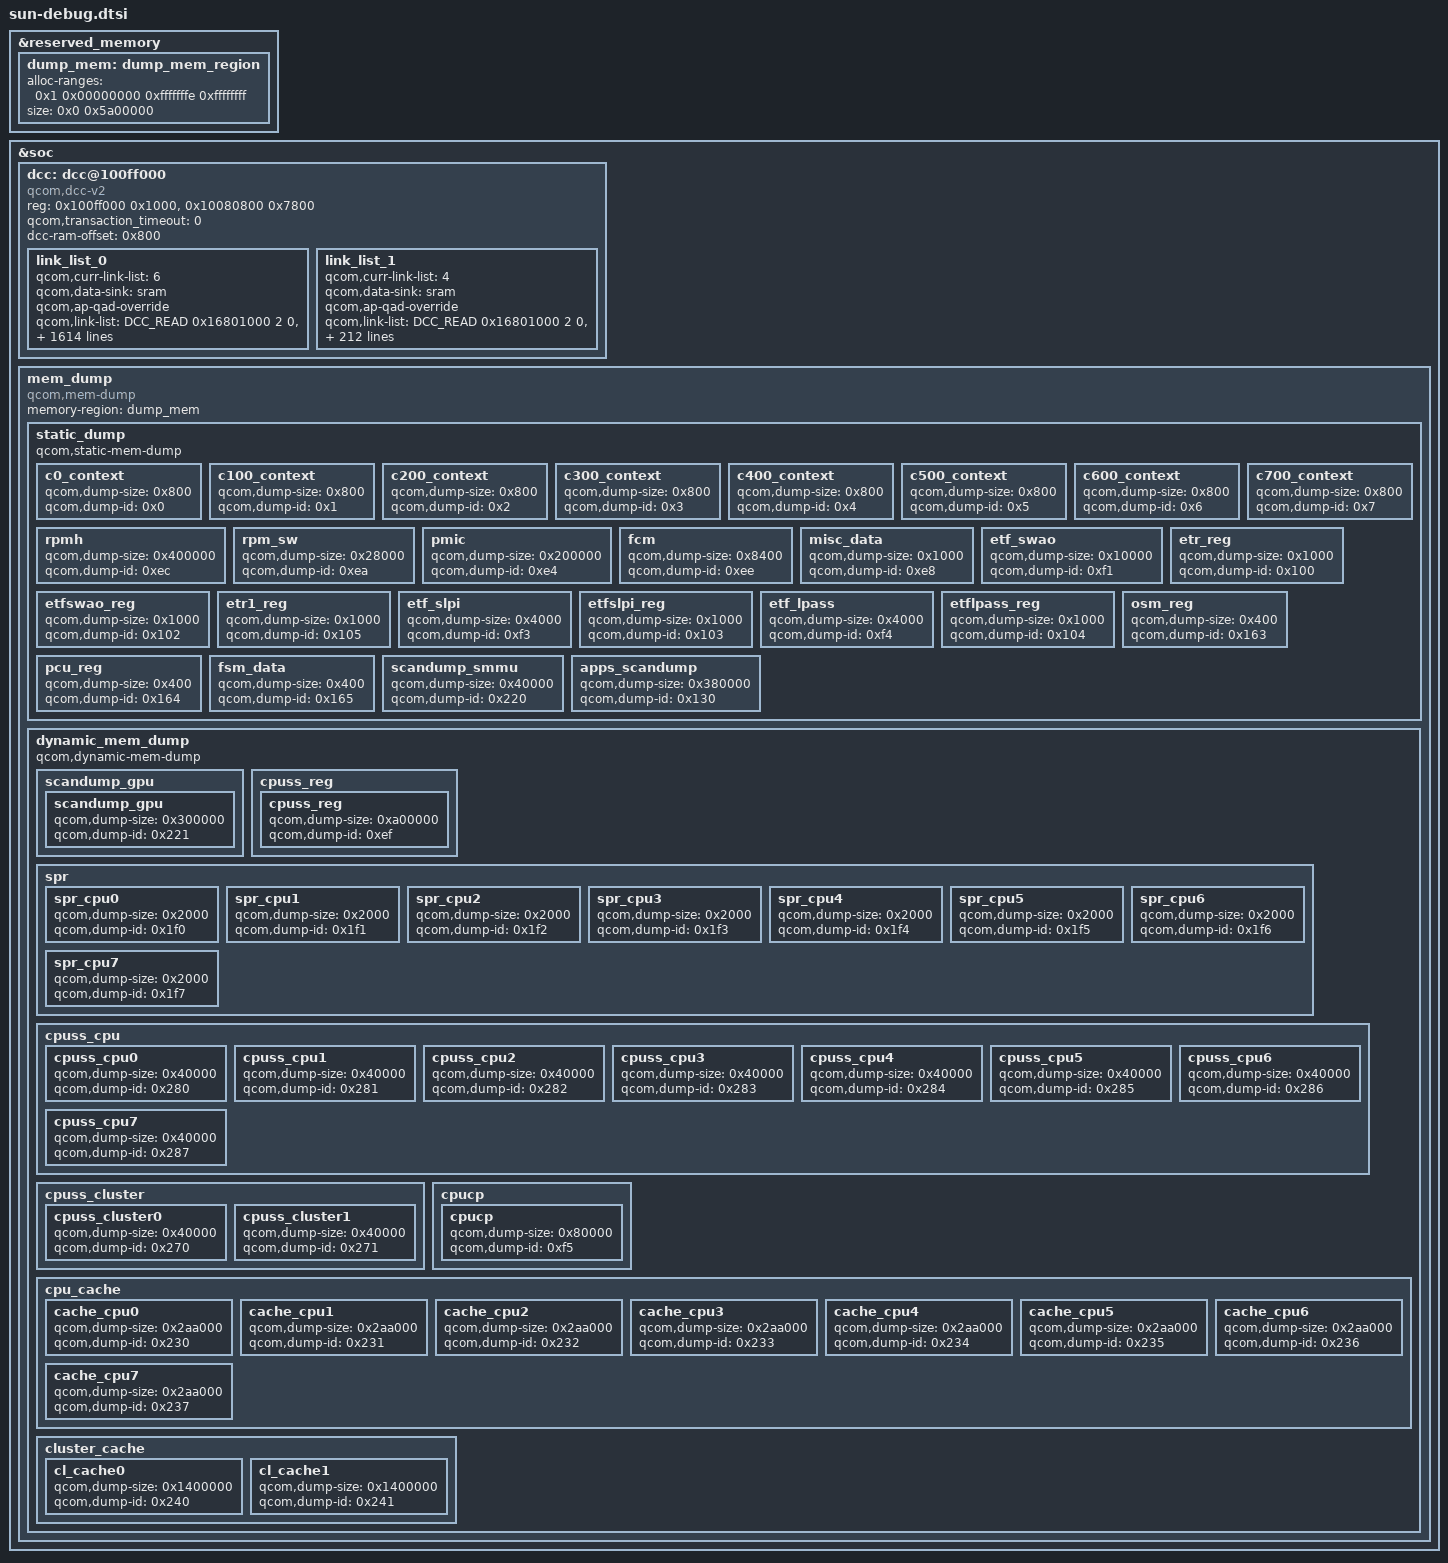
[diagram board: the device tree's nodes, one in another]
// SPDX-License-Identifier: BSD-3-Clause
/*
 * Copyright (c) 2023-2024 Qualcomm Innovation Center, Inc. All rights reserved.
 */

#include <dt-bindings/soc/qcom,dcc_v2.h>

&reserved_memory {
	#address-cells = <2>;
	#size-cells = <2>;
	ranges;

	dump_mem: dump_mem_region {
		alloc-ranges = <0x1 0x00000000 0xfffffffe 0xffffffff>;
		size = <0x0 0x5a00000>;
	};
};

&soc {
	dcc: dcc@100ff000 {
		compatible = "qcom,dcc-v2";
		reg = <0x100ff000 0x1000>,
		      <0x10080800 0x7800>;
		reg-names = "dcc-base", "dcc-ram-base";

		qcom,transaction_timeout = <0>;
		dcc-ram-offset = <0x800>;

		link_list_0 {
			qcom,curr-link-list = <6>;
			qcom,data-sink = "sram";
			qcom,ap-qad-override;
			qcom,link-list = <DCC_READ 0x16801000 2 0>,
				<DCC_READ 0x18880258 10 0>,
				<DCC_READ 0x18880288 6 0>,
				<DCC_READ 0x188802a8 10 0>,
				<DCC_READ 0x18880328 6 0>,
				<DCC_READ 0x188803d8 10 0>,
				<DCC_READ 0x18880408 2 0>,
				<DCC_READ 0x19880258 10 0>,
				<DCC_READ 0x19880288 6 0>,
				<DCC_READ 0x198802a8 10 0>,
				<DCC_READ 0x19880328 6 0>,
				<DCC_READ 0x198803d8 10 0>,
				<DCC_READ 0x19880408 2 0>,
				<DCC_READ 0x188b0000 4 0>,
				<DCC_READ 0x188b0050 2 0>,
				<DCC_READ 0x188b00e8 36 0>,
				<DCC_READ 0x188b0788 2 0>,
				<DCC_READ 0x188b0c18 2 0>,
				<DCC_READ 0x198b0000 4 0>,
				<DCC_READ 0x198b0050 2 0>,
				<DCC_READ 0x198b00e8 36 0>,
				<DCC_READ 0x198b0788 2 0>,
				<DCC_READ 0x198b0c18 2 0>,
				<DCC_READ 0x17988814 2 0>,
				<DCC_READ 0x17998814 2 0>,
				<DCC_READ 0x179d2000 3 0>,
				<DCC_READ 0x179d2020 3 0>,
				<DCC_READ 0x179d2040 2 0>,
				<DCC_READ 0x179d2060 2 0>,
				<DCC_READ 0x179d2080 2 0>,
				<DCC_READ 0x179d20a0 1 0>,
				<DCC_READ 0x179d20b0 1 0>,
				<DCC_READ 0x179d20c0 1 0>,
				<DCC_READ 0x179d2200 2 0>,
				<DCC_READ 0x179d2220 2 0>,
				<DCC_READ 0x179d2280 2 0>,
				<DCC_READ 0x179d22f0 1 0>,
				<DCC_READ 0x179d2304 1 0>,
				<DCC_READ 0x179d2310 1 0>,
				<DCC_READ 0x179d2400 4 0>,
				<DCC_READ 0x179d2420 1 0>,
				<DCC_READ 0x179d2428 2 0>,
				<DCC_READ 0x179d2440 2 0>,
				<DCC_READ 0x179d2520 2 0>,
				<DCC_READ 0x179d2600 2 0>,
				<DCC_READ 0x179d2710 2 0>,
				<DCC_READ 0x179d2720 2 0>,
				<DCC_READ 0x179d2740 2 0>,
				<DCC_READ 0x179d3080 2 0>,
				<DCC_READ 0x17846018 2 0>,
				<DCC_READ 0x17846060 1 0>,
				<DCC_READ 0x17846100 2 0>,
				<DCC_READ 0x17846110 1 0>,
				<DCC_READ 0x17847030 2 0>,
				<DCC_READ 0x17847040 2 0>,
				<DCC_READ 0x17847050 2 0>,
				<DCC_READ 0x17847060 2 0>,
				<DCC_READ 0x17847070 2 0>,
				<DCC_READ 0x17847080 2 0>,
				<DCC_READ 0x17847090 2 0>,
				<DCC_READ 0x178470a0 2 0>,
				<DCC_READ 0x178470b0 2 0>,
				<DCC_READ 0x178470c0 2 0>,
				<DCC_READ 0x17850000 2 0>,
				<DCC_READ 0x17850010 2 0>,
				<DCC_READ 0x17850030 2 0>,
				<DCC_READ 0x17850040 1 0>,
				<DCC_READ 0x17854000 1 0>,
				<DCC_READ 0x17854008 4 0>,
				<DCC_READ 0x179c8814 2 0>,
				<DCC_READ 0x179d0104 1 0>,
				<DCC_READ 0x179d0118 2 0>,
				<DCC_READ 0x179d0148 2 0>,
				<DCC_READ 0x179d1600 1 0>,
				<DCC_READ 0x179d1678 1 0>,
				<DCC_READ 0x179d1688 2 0>,
				<DCC_READ 0x179d1694 3 0>,
				<DCC_READ 0x179d1820 3 0>,
				<DCC_READ 0x17b70000 1 0>,
				<DCC_READ 0x17b70008 2 0>,
				<DCC_READ 0x17b71000 1 0>,
				<DCC_READ 0x17b71008 2 0>,
				<DCC_READ 0x164807f8 1 0>,
				<DCC_READ 0x16480810 3 0>,
				<DCC_READ 0x16483000 40 0>,
				<DCC_READ 0x16483a00 2 0>,
				<DCC_READ 0x16488908 1 0>,
				<DCC_READ 0x16488C18 1 0>,
				<DCC_READ 0x164A8908 1 0>,
				<DCC_READ 0x164A8C18 1 0>,
				<DCC_READ 0x164a07f8 1 0>,
				<DCC_READ 0x164a0810 3 0>,
				<DCC_READ 0x164a3000 40 0>,
				<DCC_READ 0x164a3a00 2 0>,
				<DCC_READ 0x16493000 40 0>,
				<DCC_READ 0x16493a00 2 0>,
				<DCC_READ 0x16498C18 1 0>,
				<DCC_READ 0x164B8C18 1 0>,
				<DCC_READ 0x164b3a00 2 0>,
				<DCC_READ 0x16440000 2 0>,
				<DCC_READ 0x16440020 3 0>,
				<DCC_READ 0x16440030 1 0>,
				<DCC_READ 0x1644003c 1 0>,
				<DCC_READ 0x16440044 3 0>,
				<DCC_READ 0x16440438 1 0>,
				<DCC_READ 0x16440500 5 0>,
				<DCC_READ 0x16562000 2 0>,
				<DCC_READ 0x16565004 1 0>,
				<DCC_READ 0x17000BD0 1 0>,
				<DCC_READ 0x170404A0 1 0>,
				<DCC_READ 0x170A0590 1 0>,
				<DCC_READ 0x170C0330 1 0>,
				<DCC_READ 0x170C0338 1 0>,
				<DCC_READ 0x170C0340 1 0>,
				<DCC_READ 0x170C0518 1 0>,
				<DCC_READ 0x170C0528 1 0>,
				<DCC_READ 0x170C0538 1 0>,
				<DCC_READ 0x170C0560 4 0>,
				<DCC_READ 0x17200BD0 1 0>,
				<DCC_READ 0x172404A0 1 0>,
				<DCC_READ 0x172A0590 1 0>,
				<DCC_READ 0x172C0330 1 0>,
				<DCC_READ 0x172C0338 1 0>,
				<DCC_READ 0x172C0340 1 0>,
				<DCC_READ 0x172C0518 1 0>,
				<DCC_READ 0x172C0528 1 0>,
				<DCC_READ 0x172C0538 1 0>,
				<DCC_READ 0x172C0560 4 0>,
				<DCC_READ 0x1641000C 1 0>,
				<DCC_READ 0x1641400C 1 0>,
				<DCC_READ 0x18830320 2 0>,
				<DCC_READ 0x19830320 2 0>,
				<DCC_READ 0x18040010 6 0>,
				<DCC_READ 0x18040040 10 0>,
				<DCC_READ 0x18040090 6 0>,
				<DCC_READ 0x18850020 2 0>,
				<DCC_READ 0x18850060 2 0>,
				<DCC_READ 0x188500A0 2 0>,
				<DCC_READ 0x188500E0 2 0>,
				<DCC_READ 0x18850120 2 0>,
				<DCC_READ 0x18850160 2 0>,
				<DCC_READ 0x189C1000 1 0>,
				<DCC_READ 0x199C1000 1 0>,
				<DCC_READ 0x18A30000 9 0>,
				<DCC_READ 0x18A30030 1 0>,
				<DCC_READ 0x18A3003C 2 0>,
				<DCC_READ 0x19A30000 9 0>,
				<DCC_READ 0x19A30030 1 0>,
				<DCC_READ 0x19A3003C 2 0>,
				<DCC_READ 0x24201040 1 0>,
				<DCC_READ 0x24201048 1 0>,
				<DCC_READ 0x24100010 1 0>,
				<DCC_READ 0x24100020 6 0>,
				<DCC_READ 0x24180010 1 0>,
				<DCC_READ 0x24180020 6 0>,
				<DCC_READ 0x24200010 1 0>,
				<DCC_READ 0x24200020 6 0>,
				<DCC_READ 0x24200410 1 0>,
				<DCC_READ 0x24200420 6 0>,
				<DCC_READ 0x24102010 1 0>,
				<DCC_READ 0x24102038 1 0>,
				<DCC_READ 0x24102030 2 0>,
				<DCC_READ 0x24102030 2 0>,
				<DCC_READ 0x24102030 2 0>,
				<DCC_READ 0x24102030 2 0>,
				<DCC_READ 0x24102038 1 0>,
				<DCC_READ 0x24102030 2 0>,
				<DCC_READ 0x24102030 2 0>,
				<DCC_READ 0x24102030 2 0>,
				<DCC_READ 0x24102030 2 0>,
				<DCC_READ 0x24102038 1 0>,
				<DCC_READ 0x24102030 2 0>,
				<DCC_READ 0x24102030 2 0>,
				<DCC_READ 0x24102030 2 0>,
				<DCC_READ 0x24102030 2 0>,
				<DCC_READ 0x24102038 1 0>,
				<DCC_READ 0x24102030 2 0>,
				<DCC_READ 0x24102030 2 0>,
				<DCC_READ 0x24102030 2 0>,
				<DCC_READ 0x24102030 2 0>,
				<DCC_READ 0x24102008 2 0>,
				<DCC_READ 0x24181010 1 0>,
				<DCC_READ 0x24181038 1 0>,
				<DCC_READ 0x24181030 2 0>,
				<DCC_READ 0x24181030 2 0>,
				<DCC_READ 0x24181030 2 0>,
				<DCC_READ 0x24181030 2 0>,
				<DCC_READ 0x24181038 1 0>,
				<DCC_READ 0x24181030 2 0>,
				<DCC_READ 0x24181030 2 0>,
				<DCC_READ 0x24181030 2 0>,
				<DCC_READ 0x24181030 2 0>,
				<DCC_READ 0x24181038 1 0>,
				<DCC_READ 0x24181030 2 0>,
				<DCC_READ 0x24181030 2 0>,
				<DCC_READ 0x24181030 2 0>,
				<DCC_READ 0x24181030 2 0>,
				<DCC_READ 0x24181038 1 0>,
				<DCC_READ 0x24181030 2 0>,
				<DCC_READ 0x24181030 2 0>,
				<DCC_READ 0x24181030 2 0>,
				<DCC_READ 0x24181030 2 0>,
				<DCC_READ 0x24181008 2 0>,
				<DCC_READ 0x24203010 1 0>,
				<DCC_READ 0x24203038 1 0>,
				<DCC_READ 0x24203030 2 0>,
				<DCC_READ 0x24203030 2 0>,
				<DCC_READ 0x24203030 2 0>,
				<DCC_READ 0x24203030 2 0>,
				<DCC_READ 0x24203038 1 0>,
				<DCC_READ 0x24203030 2 0>,
				<DCC_READ 0x24203030 2 0>,
				<DCC_READ 0x24203030 2 0>,
				<DCC_READ 0x24203030 2 0>,
				<DCC_READ 0x24203038 1 0>,
				<DCC_READ 0x24203030 2 0>,
				<DCC_READ 0x24203030 2 0>,
				<DCC_READ 0x24203030 2 0>,
				<DCC_READ 0x24203030 2 0>,
				<DCC_READ 0x24203038 1 0>,
				<DCC_READ 0x24203030 2 0>,
				<DCC_READ 0x24203030 2 0>,
				<DCC_READ 0x24203030 2 0>,
				<DCC_READ 0x24203030 2 0>,
				<DCC_READ 0x24203008 2 0>,
				<DCC_READ 0x24203410 1 0>,
				<DCC_READ 0x24203438 1 0>,
				<DCC_READ 0x24203430 2 0>,
				<DCC_READ 0x24203430 2 0>,
				<DCC_READ 0x24203430 2 0>,
				<DCC_READ 0x24203430 2 0>,
				<DCC_READ 0x24203438 1 0>,
				<DCC_READ 0x24203430 2 0>,
				<DCC_READ 0x24203430 2 0>,
				<DCC_READ 0x24203430 2 0>,
				<DCC_READ 0x24203430 2 0>,
				<DCC_READ 0x24203438 1 0>,
				<DCC_READ 0x24203430 2 0>,
				<DCC_READ 0x24203430 2 0>,
				<DCC_READ 0x24203430 2 0>,
				<DCC_READ 0x24203430 2 0>,
				<DCC_READ 0x24203438 1 0>,
				<DCC_READ 0x24203430 2 0>,
				<DCC_READ 0x24203430 2 0>,
				<DCC_READ 0x24203430 2 0>,
				<DCC_READ 0x24203430 2 0>,
				<DCC_READ 0x24203408 2 0>,
				<DCC_READ 0x24104018 1 0>,
				<DCC_READ 0x24104008 1 0>,
				<DCC_READ 0x24104010 2 0>,
				<DCC_READ 0x24104010 2 0>,
				<DCC_READ 0x24104010 2 0>,
				<DCC_READ 0x24104010 2 0>,
				<DCC_READ 0x24104098 1 0>,
				<DCC_READ 0x24104088 1 0>,
				<DCC_READ 0x24104090 2 0>,
				<DCC_READ 0x24104090 2 0>,
				<DCC_READ 0x24104090 2 0>,
				<DCC_READ 0x24104090 2 0>,
				<DCC_READ 0x24104090 2 0>,
				<DCC_READ 0x24182018 1 0>,
				<DCC_READ 0x24182008 1 0>,
				<DCC_READ 0x24182010 2 0>,
				<DCC_READ 0x24182010 2 0>,
				<DCC_READ 0x24182010 2 0>,
				<DCC_READ 0x24182010 2 0>,
				<DCC_READ 0x24182098 1 0>,
				<DCC_READ 0x24182088 1 0>,
				<DCC_READ 0x24182090 2 0>,
				<DCC_READ 0x24182090 2 0>,
				<DCC_READ 0x24182090 2 0>,
				<DCC_READ 0x24182090 2 0>,
				<DCC_READ 0x24182090 2 0>,
				<DCC_READ 0x24204018 1 0>,
				<DCC_READ 0x24204008 1 0>,
				<DCC_READ 0x24204010 2 0>,
				<DCC_READ 0x24204010 2 0>,
				<DCC_READ 0x24204010 2 0>,
				<DCC_READ 0x24204098 1 0>,
				<DCC_READ 0x24204088 1 0>,
				<DCC_READ 0x24204090 2 0>,
				<DCC_READ 0x24204090 2 0>,
				<DCC_READ 0x24204090 2 0>,
				<DCC_READ 0x24204090 2 0>,
				<DCC_READ 0x24204090 2 0>,
				<DCC_READ 0x24204090 2 0>,
				<DCC_READ 0x24204090 2 0>,
				<DCC_READ 0x24204090 2 0>,
				<DCC_READ 0x24204090 2 0>,
				<DCC_READ 0x24204090 2 0>,
				<DCC_READ 0x24204090 2 0>,
				<DCC_READ 0x24204090 2 0>,
				<DCC_WRITE 0x24102028 0x2 0>,
				<DCC_LOOP 0x40 0 0>,
				<DCC_READ 0x24102030 2 0>,
				<DCC_READ 0x24102030 2 0>,
				<DCC_READ 0x24102030 2 0>,
				<DCC_READ 0x24102030 2 0>,
				<DCC_LOOP 0x1 0 0>,
				<DCC_WRITE 0x24102028 0x1 0>,
				<DCC_WRITE 0x24181028 0x2 0>,
				<DCC_LOOP 0x40 0 0>,
				<DCC_READ 0x24181030 2 0>,
				<DCC_READ 0x24181030 2 0>,
				<DCC_READ 0x24181030 2 0>,
				<DCC_READ 0x24181030 2 0>,
				<DCC_LOOP 0x1 0 0>,
				<DCC_WRITE 0x24181028 0x1 0>,
				<DCC_READ 0x16801000 2 0>,
				<DCC_READ 0x240BA050 1 0>,
				<DCC_READ 0x240BA164 1 0>,
				<DCC_READ 0x240BA280 1 0>,
				<DCC_READ 0x240BA288 1 0>,
				<DCC_READ 0x240BA28C 1 0>,
				<DCC_READ 0x240BA290 1 0>,
				<DCC_READ 0x240BA294 1 0>,
				<DCC_READ 0x240BA298 1 0>,
				<DCC_READ 0x240BA29C 1 0>,
				<DCC_READ 0x240BA2A0 1 0>,
				<DCC_READ 0x240BA2A4 1 0>,
				<DCC_READ 0x240BA2C0 1 0>,
				<DCC_READ 0x240BA2C4 1 0>,
				<DCC_READ 0x24BC0610 1 0>,
				<DCC_READ 0x24BC0614 1 0>,
				<DCC_READ 0x24BC0618 1 0>,
				<DCC_READ 0x24BC061C 1 0>,
				<DCC_READ 0x24BC0620 1 0>,
				<DCC_READ 0x24BC0624 1 0>,
				<DCC_READ 0x24BC0628 1 0>,
				<DCC_READ 0x24BC062C 1 0>,
				<DCC_READ 0x24BC0630 1 0>,
				<DCC_READ 0x24BC0634 1 0>,
				<DCC_READ 0x24BC0638 1 0>,
				<DCC_READ 0x24BC0640 1 0>,
				<DCC_READ 0x24BC0644 1 0>,
				<DCC_READ 0x24BC06A0 1 0>,
				<DCC_READ 0x24FC0610 1 0>,
				<DCC_READ 0x24FC0614 1 0>,
				<DCC_READ 0x24FC0618 1 0>,
				<DCC_READ 0x24FC061C 1 0>,
				<DCC_READ 0x24FC0620 1 0>,
				<DCC_READ 0x24FC0624 1 0>,
				<DCC_READ 0x24FC0628 1 0>,
				<DCC_READ 0x24FC062C 1 0>,
				<DCC_READ 0x24FC0630 1 0>,
				<DCC_READ 0x24FC0634 1 0>,
				<DCC_READ 0x24FC0638 1 0>,
				<DCC_READ 0x24FC0640 1 0>,
				<DCC_READ 0x24FC0644 1 0>,
				<DCC_READ 0x24FC06A0 1 0>,
				<DCC_READ 0x25BC0610 1 0>,
				<DCC_READ 0x25BC0614 1 0>,
				<DCC_READ 0x25BC0618 1 0>,
				<DCC_READ 0x25BC061C 1 0>,
				<DCC_READ 0x25BC0620 1 0>,
				<DCC_READ 0x25BC0624 1 0>,
				<DCC_READ 0x25BC0628 1 0>,
				<DCC_READ 0x25BC062C 1 0>,
				<DCC_READ 0x25BC0630 1 0>,
				<DCC_READ 0x25BC0634 1 0>,
				<DCC_READ 0x25BC0638 1 0>,
				<DCC_READ 0x25BC0640 1 0>,
				<DCC_READ 0x25BC0644 1 0>,
				<DCC_READ 0x25BC06A0 1 0>,
				<DCC_READ 0x25FC0610 1 0>,
				<DCC_READ 0x25FC0614 1 0>,
				<DCC_READ 0x25FC0618 1 0>,
				<DCC_READ 0x25FC061C 1 0>,
				<DCC_READ 0x25FC0620 1 0>,
				<DCC_READ 0x25FC0624 1 0>,
				<DCC_READ 0x25FC0628 1 0>,
				<DCC_READ 0x25FC062C 1 0>,
				<DCC_READ 0x25FC0630 1 0>,
				<DCC_READ 0x25FC0634 1 0>,
				<DCC_READ 0x25FC0638 1 0>,
				<DCC_READ 0x25FC0640 1 0>,
				<DCC_READ 0x25FC0644 1 0>,
				<DCC_READ 0x25FC06A0 1 0>,
				<DCC_READ 0x240A801C 1 0>,
				<DCC_READ 0x240A8020 1 0>,
				<DCC_READ 0x240A8038 1 0>,
				<DCC_READ 0x240A803C 1 0>,
				<DCC_READ 0x240A8040 1 0>,
				<DCC_READ 0x240A8058 1 0>,
				<DCC_READ 0x240A805C 1 0>,
				<DCC_READ 0x240A8060 1 0>,
				<DCC_READ 0x240A8064 1 0>,
				<DCC_READ 0x240A8068 1 0>,
				<DCC_READ 0x240A8074 1 0>,
				<DCC_READ 0x240A8078 1 0>,
				<DCC_READ 0x240A807C 1 0>,
				<DCC_READ 0x240A8080 1 0>,
				<DCC_READ 0x240A80A8 1 0>,
				<DCC_READ 0x240A80B8 1 0>,
				<DCC_READ 0x240A80EC 1 0>,
				<DCC_READ 0x240A80F0 1 0>,
				<DCC_READ 0x240A80F4 1 0>,
				<DCC_READ 0x240A80F8 1 0>,
				<DCC_READ 0x240A80FC 1 0>,
				<DCC_READ 0x240A8140 1 0>,
				<DCC_READ 0x240A8164 1 0>,
				<DCC_READ 0x240A8168 1 0>,
				<DCC_READ 0x240A81C4 1 0>,
				<DCC_READ 0x240A81C8 1 0>,
				<DCC_READ 0x240A81DC 1 0>,
				<DCC_READ 0x240A81E0 1 0>,
				<DCC_READ 0x240A844C 1 0>,
				<DCC_READ 0x240A845C 1 0>,
				<DCC_READ 0x240A84C8 1 0>,
				<DCC_READ 0x240A84CC 1 0>,
				<DCC_READ 0x240A84D0 1 0>,
				<DCC_READ 0x240A84D4 1 0>,
				<DCC_READ 0x240A84D8 1 0>,
				<DCC_READ 0x240A84DC 1 0>,
				<DCC_READ 0x240A84E0 1 0>,
				<DCC_READ 0x240A84E4 1 0>,
				<DCC_READ 0x240A84E8 1 0>,
				<DCC_READ 0x240A84EC 1 0>,
				<DCC_READ 0x240A84F0 1 0>,
				<DCC_READ 0x240A84F4 1 0>,
				<DCC_READ 0x240A84F8 1 0>,
				<DCC_READ 0x240A84FC 1 0>,
				<DCC_READ 0x240A8500 1 0>,
				<DCC_READ 0x240A8504 1 0>,
				<DCC_READ 0x240A8508 1 0>,
				<DCC_READ 0x240A850C 1 0>,
				<DCC_READ 0x240A8510 1 0>,
				<DCC_READ 0x240A8514 1 0>,
				<DCC_READ 0x240A8518 1 0>,
				<DCC_READ 0x240A851C 1 0>,
				<DCC_READ 0x240A8520 1 0>,
				<DCC_READ 0x240A8524 1 0>,
				<DCC_READ 0x240A8528 1 0>,
				<DCC_READ 0x240A852C 1 0>,
				<DCC_READ 0x240A8530 1 0>,
				<DCC_READ 0x240A9000 1 0>,
				<DCC_READ 0x240A9004 1 0>,
				<DCC_READ 0x240A9010 1 0>,
				<DCC_READ 0x240A9014 1 0>,
				<DCC_READ 0x240A9020 1 0>,
				<DCC_READ 0x240A9024 1 0>,
				<DCC_READ 0x240A9028 1 0>,
				<DCC_READ 0x240A9034 1 0>,
				<DCC_READ 0x240A9038 1 0>,
				<DCC_READ 0x240A9130 1 0>,
				<DCC_READ 0x240A9134 1 0>,
				<DCC_READ 0x240A9138 1 0>,
				<DCC_READ 0x240A9140 1 0>,
				<DCC_READ 0x240A9144 1 0>,
				<DCC_READ 0x240A9148 1 0>,
				<DCC_READ 0x240A914C 1 0>,
				<DCC_READ 0x240A9150 1 0>,
				<DCC_READ 0x240A9154 1 0>,
				<DCC_READ 0x240A9158 1 0>,
				<DCC_READ 0x240A915C 1 0>,
				<DCC_READ 0x240A9160 1 0>,
				<DCC_READ 0x240A9164 1 0>,
				<DCC_READ 0x240A9168 1 0>,
				<DCC_READ 0x240A916C 1 0>,
				<DCC_READ 0x240A9170 1 0>,
				<DCC_READ 0x240A9174 1 0>,
				<DCC_READ 0x240A9178 1 0>,
				<DCC_READ 0x240A917C 1 0>,
				<DCC_READ 0x240A9180 1 0>,
				<DCC_READ 0x240A9184 1 0>,
				<DCC_READ 0x240A91AC 1 0>,
				<DCC_READ 0x240A91B0 1 0>,
				<DCC_READ 0x240A91B4 1 0>,
				<DCC_READ 0x240A91B8 1 0>,
				<DCC_READ 0x240A91BC 1 0>,
				<DCC_READ 0x240A91C0 1 0>,
				<DCC_READ 0x240A91C8 1 0>,
				<DCC_READ 0x240A920C 1 0>,
				<DCC_READ 0x240A9220 1 0>,
				<DCC_READ 0x240A9224 1 0>,
				<DCC_READ 0x240A9264 1 0>,
				<DCC_READ 0x240A9294 1 0>,
				<DCC_READ 0x240A9298 1 0>,
				<DCC_READ 0x240A929C 1 0>,
				<DCC_READ 0x240A92A0 1 0>,
				<DCC_READ 0x240A92A4 1 0>,
				<DCC_READ 0x240A92A8 1 0>,
				<DCC_READ 0x240A92AC 1 0>,
				<DCC_READ 0x240A92B8 1 0>,
				<DCC_READ 0x240A92F8 1 0>,
				<DCC_READ 0x24800004 1 0>,
				<DCC_READ 0x24801004 1 0>,
				<DCC_READ 0x24802004 1 0>,
				<DCC_READ 0x24803004 1 0>,
				<DCC_READ 0x24804004 1 0>,
				<DCC_READ 0x24805004 1 0>,
				<DCC_READ 0x24806004 1 0>,
				<DCC_READ 0x24807004 1 0>,
				<DCC_READ 0x24808004 1 0>,
				<DCC_READ 0x24809004 1 0>,
				<DCC_READ 0x2480a004 1 0>,
				<DCC_READ 0x2480b004 1 0>,
				<DCC_READ 0x2480c004 1 0>,
				<DCC_READ 0x2480d004 1 0>,
				<DCC_READ 0x2480e004 1 0>,
				<DCC_READ 0x2480f004 1 0>,
				<DCC_READ 0x24810004 1 0>,
				<DCC_READ 0x24811004 1 0>,
				<DCC_READ 0x24812004 1 0>,
				<DCC_READ 0x24813004 1 0>,
				<DCC_READ 0x24814004 1 0>,
				<DCC_READ 0x24815004 1 0>,
				<DCC_READ 0x24816004 1 0>,
				<DCC_READ 0x24817004 1 0>,
				<DCC_READ 0x24818004 1 0>,
				<DCC_READ 0x24819004 1 0>,
				<DCC_READ 0x2481a004 1 0>,
				<DCC_READ 0x2481b004 1 0>,
				<DCC_READ 0x2481c004 1 0>,
				<DCC_READ 0x2481d004 1 0>,
				<DCC_READ 0x2481e004 1 0>,
				<DCC_READ 0x2481f004 1 0>,
				<DCC_READ 0x24820004 1 0>,
				<DCC_READ 0x24821004 1 0>,
				<DCC_READ 0x24822004 1 0>,
				<DCC_READ 0x24823004 1 0>,
				<DCC_READ 0x24843350 1 0>,
				<DCC_READ 0x24843354 1 0>,
				<DCC_READ 0x248433F4 1 0>,
				<DCC_READ 0x248433F8 1 0>,
				<DCC_READ 0x248433FC 1 0>,
				<DCC_READ 0x24843400 1 0>,
				<DCC_READ 0x24843404 1 0>,
				<DCC_READ 0x24843408 1 0>,
				<DCC_READ 0x2484340C 1 0>,
				<DCC_READ 0x24843410 1 0>,
				<DCC_READ 0x24843414 1 0>,
				<DCC_READ 0x24843418 1 0>,
				<DCC_READ 0x2484341C 1 0>,
				<DCC_READ 0x248434C0 1 0>,
				<DCC_READ 0x248434C4 1 0>,
				<DCC_READ 0x248434C8 1 0>,
				<DCC_READ 0x248434CC 1 0>,
				<DCC_READ 0x248434D0 1 0>,
				<DCC_READ 0x248434D4 1 0>,
				<DCC_READ 0x24843600 1 0>,
				<DCC_READ 0x2484360C 1 0>,
				<DCC_READ 0x24845040 1 0>,
				<DCC_READ 0x24845048 1 0>,
				<DCC_READ 0x24845050 1 0>,
				<DCC_READ 0x24845058 1 0>,
				<DCC_READ 0x24845060 1 0>,
				<DCC_READ 0x24845068 1 0>,
				<DCC_READ 0x24845070 1 0>,
				<DCC_READ 0x24845074 1 0>,
				<DCC_READ 0x24845078 1 0>,
				<DCC_READ 0x2484507C 1 0>,
				<DCC_READ 0x24845090 1 0>,
				<DCC_READ 0x24845094 1 0>,
				<DCC_READ 0x24845098 1 0>,
				<DCC_READ 0x2484509C 1 0>,
				<DCC_READ 0x248450A0 1 0>,
				<DCC_READ 0x248450A4 1 0>,
				<DCC_READ 0x248450A8 1 0>,
				<DCC_READ 0x248450AC 1 0>,
				<DCC_READ 0x248450B0 1 0>,
				<DCC_READ 0x248450B4 1 0>,
				<DCC_READ 0x248450B8 1 0>,
				<DCC_READ 0x248450BC 1 0>,
				<DCC_READ 0x248450C0 1 0>,
				<DCC_READ 0x248450C4 1 0>,
				<DCC_READ 0x248450CC 1 0>,
				<DCC_READ 0x248450D0 1 0>,
				<DCC_READ 0x24845240 1 0>,
				<DCC_READ 0x248452A0 1 0>,
				<DCC_READ 0x24845300 1 0>,
				<DCC_READ 0x24845310 1 0>,
				<DCC_READ 0x24845320 1 0>,
				<DCC_READ 0x24845330 1 0>,
				<DCC_READ 0x24845334 1 0>,
				<DCC_READ 0x24845338 1 0>,
				<DCC_READ 0x24847404 1 0>,
				<DCC_READ 0x2484740C 1 0>,
				<DCC_READ 0x24847410 1 0>,
				<DCC_READ 0x24847414 1 0>,
				<DCC_READ 0x24847448 1 0>,
				<DCC_READ 0x24847450 1 0>,
				<DCC_READ 0x24847458 1 0>,
				<DCC_READ 0x2484745C 1 0>,
				<DCC_READ 0x24847600 1 0>,
				<DCC_READ 0x24849000 1 0>,
				<DCC_READ 0x24849010 1 0>,
				<DCC_READ 0x2487C000 1 0>,
				<DCC_READ 0x2487C01C 1 0>,
				<DCC_READ 0x2487C020 1 0>,
				<DCC_READ 0x2487C024 1 0>,
				<DCC_READ 0x2487C030 1 0>,
				<DCC_READ 0x2487C034 1 0>,
				<DCC_READ 0x2487C038 1 0>,
				<DCC_READ 0x2487C03C 1 0>,
				<DCC_READ 0x2487C040 1 0>,
				<DCC_READ 0x2487C044 1 0>,
				<DCC_READ 0x2487C048 1 0>,
				<DCC_READ 0x2487C04C 1 0>,
				<DCC_READ 0x2487C054 1 0>,
				<DCC_READ 0x2487C058 1 0>,
				<DCC_READ 0x2487C078 1 0>,
				<DCC_READ 0x2487C108 1 0>,
				<DCC_READ 0x2487C10C 1 0>,
				<DCC_READ 0x2487C110 1 0>,
				<DCC_READ 0x2487C114 1 0>,
				<DCC_READ 0x2487C118 1 0>,
				<DCC_READ 0x2487C11C 1 0>,
				<DCC_READ 0x2487C120 1 0>,
				<DCC_READ 0x2487C124 1 0>,
				<DCC_READ 0x2487C128 1 0>,
				<DCC_READ 0x2487C20C 1 0>,
				<DCC_READ 0x2487C210 1 0>,
				<DCC_READ 0x2487C214 1 0>,
				<DCC_READ 0x248A600C 1 0>,
				<DCC_READ 0x248A6010 1 0>,
				<DCC_READ 0x248A6014 1 0>,
				<DCC_READ 0x248A6018 1 0>,
				<DCC_READ 0x248A6020 1 0>,
				<DCC_READ 0x248A6024 1 0>,
				<DCC_READ 0x248A6028 1 0>,
				<DCC_READ 0x248A6034 1 0>,
				<DCC_READ 0x248A6038 1 0>,
				<DCC_READ 0x248A6040 1 0>,
				<DCC_READ 0x248A6050 1 0>,
				<DCC_READ 0x248A6058 1 0>,
				<DCC_READ 0x248A6060 1 0>,
				<DCC_READ 0x248A6064 1 0>,
				<DCC_READ 0x248A6068 1 0>,
				<DCC_READ 0x248A606C 1 0>,
				<DCC_READ 0x248A7020 1 0>,
				<DCC_READ 0x248A7030 1 0>,
				<DCC_READ 0x248A7034 1 0>,
				<DCC_READ 0x248A7078 1 0>,
				<DCC_READ 0x248A707C 1 0>,
				<DCC_READ 0x248a7080 1 0>,
				<DCC_READ 0x248A7084 1 0>,
				<DCC_READ 0x248a708c 1 0>,
				<DCC_READ 0x248A7090 1 0>,
				<DCC_READ 0x248A7094 1 0>,
				<DCC_READ 0x248A7098 1 0>,
				<DCC_READ 0x248A709C 1 0>,
				<DCC_READ 0x248A70A0 1 0>,
				<DCC_READ 0x248E002C 1 0>,
				<DCC_READ 0x248E009C 1 0>,
				<DCC_READ 0x248E00A0 1 0>,
				<DCC_READ 0x248E00A8 1 0>,
				<DCC_READ 0x248E00AC 1 0>,
				<DCC_READ 0x248E00B0 1 0>,
				<DCC_READ 0x248E00B8 1 0>,
				<DCC_READ 0x248E00C0 1 0>,
				<DCC_READ 0x248E00C4 1 0>,
				<DCC_READ 0x248E00C8 1 0>,
				<DCC_READ 0x248E00CC 1 0>,
				<DCC_READ 0x248E00D0 1 0>,
				<DCC_READ 0x248E00D4 1 0>,
				<DCC_READ 0x248E00D8 1 0>,
				<DCC_READ 0x248E00E0 1 0>,
				<DCC_READ 0x248E00E8 1 0>,
				<DCC_READ 0x248E00F0 1 0>,
				<DCC_READ 0x248E00F8 1 0>,
				<DCC_READ 0x248E0100 1 0>,
				<DCC_READ 0x248E0108 1 0>,
				<DCC_READ 0x248E0110 1 0>,
				<DCC_READ 0x248E0118 1 0>,
				<DCC_READ 0x248E0120 1 0>,
				<DCC_READ 0x248E0128 1 0>,
				<DCC_READ 0x248E0150 1 0>,
				<DCC_READ 0x248E0154 1 0>,
				<DCC_READ 0x248E0158 1 0>,
				<DCC_READ 0x248E015C 1 0>,
				<DCC_READ 0x248E0164 1 0>,
				<DCC_READ 0x248E01E8 1 0>,
				<DCC_READ 0x248E1010 1 0>,
				<DCC_READ 0x248E1060 1 0>,
				<DCC_READ 0x248E1064 1 0>,
				<DCC_READ 0x248E1068 1 0>,
				<DCC_READ 0x248E1070 1 0>,
				<DCC_READ 0x248E1084 1 0>,
				<DCC_READ 0x248E1088 1 0>,
				<DCC_READ 0x248E108C 1 0>,
				<DCC_READ 0x248E3004 1 0>,
				<DCC_READ 0x248E300C 1 0>,
				<DCC_READ 0x248E4004 1 0>,
				<DCC_READ 0x248E4010 1 0>,
				<DCC_READ 0x248E4014 1 0>,
				<DCC_READ 0x248E4024 1 0>,
				<DCC_READ 0x248E4028 1 0>,
				<DCC_READ 0x248E4038 1 0>,
				<DCC_READ 0x248E403C 1 0>,
				<DCC_READ 0x248E600C 1 0>,
				<DCC_READ 0x248E6010 1 0>,
				<DCC_READ 0x248E6014 1 0>,
				<DCC_READ 0x248E6018 1 0>,
				<DCC_READ 0x248E601C 1 0>,
				<DCC_READ 0x248E700C 1 0>,
				<DCC_READ 0x248E7010 1 0>,
				<DCC_READ 0x248E7014 1 0>,
				<DCC_READ 0x248E7018 1 0>,
				<DCC_READ 0x248E701C 1 0>,
				<DCC_READ 0x248E9004 1 0>,
				<DCC_READ 0x248E9010 1 0>,
				<DCC_READ 0x248E9014 1 0>,
				<DCC_READ 0x248E9018 1 0>,
				<DCC_READ 0x248E9020 1 0>,
				<DCC_READ 0x248E9024 1 0>,
				<DCC_READ 0x248E9028 1 0>,
				<DCC_READ 0x248E9030 1 0>,
				<DCC_READ 0x248E9034 1 0>,
				<DCC_READ 0x248E9038 1 0>,
				<DCC_READ 0x248E9040 1 0>,
				<DCC_READ 0x248E9044 1 0>,
				<DCC_READ 0x248E9048 1 0>,
				<DCC_READ 0x248E9050 1 0>,
				<DCC_READ 0x248E9054 1 0>,
				<DCC_READ 0x248E9058 1 0>,
				<DCC_READ 0x248EA004 1 0>,
				<DCC_READ 0x248EA010 1 0>,
				<DCC_READ 0x248EA014 1 0>,
				<DCC_READ 0x248EA018 1 0>,
				<DCC_READ 0x248EA020 1 0>,
				<DCC_READ 0x248EA024 1 0>,
				<DCC_READ 0x248EA028 1 0>,
				<DCC_READ 0x248EA030 1 0>,
				<DCC_READ 0x248EA034 1 0>,
				<DCC_READ 0x248EA038 1 0>,
				<DCC_READ 0x248EA040 1 0>,
				<DCC_READ 0x248EA044 1 0>,
				<DCC_READ 0x248EA048 1 0>,
				<DCC_READ 0x248EA050 1 0>,
				<DCC_READ 0x248EA054 1 0>,
				<DCC_READ 0x248EA058 1 0>,
				<DCC_READ 0x248F001C 1 0>,
				<DCC_READ 0x248F0050 1 0>,
				<DCC_READ 0x248F0058 1 0>,
				<DCC_READ 0x24c00004 1 0>,
				<DCC_READ 0x24c01004 1 0>,
				<DCC_READ 0x24c02004 1 0>,
				<DCC_READ 0x24c03004 1 0>,
				<DCC_READ 0x24c04004 1 0>,
				<DCC_READ 0x24c05004 1 0>,
				<DCC_READ 0x24c06004 1 0>,
				<DCC_READ 0x24c07004 1 0>,
				<DCC_READ 0x24c08004 1 0>,
				<DCC_READ 0x24c09004 1 0>,
				<DCC_READ 0x24c0a004 1 0>,
				<DCC_READ 0x24c0b004 1 0>,
				<DCC_READ 0x24c0c004 1 0>,
				<DCC_READ 0x24c0d004 1 0>,
				<DCC_READ 0x24c0e004 1 0>,
				<DCC_READ 0x24c0f004 1 0>,
				<DCC_READ 0x24c10004 1 0>,
				<DCC_READ 0x24c11004 1 0>,
				<DCC_READ 0x24c12004 1 0>,
				<DCC_READ 0x24c13004 1 0>,
				<DCC_READ 0x24c14004 1 0>,
				<DCC_READ 0x24c15004 1 0>,
				<DCC_READ 0x24c16004 1 0>,
				<DCC_READ 0x24c17004 1 0>,
				<DCC_READ 0x24c18004 1 0>,
				<DCC_READ 0x24c19004 1 0>,
				<DCC_READ 0x24c1a004 1 0>,
				<DCC_READ 0x24c1b004 1 0>,
				<DCC_READ 0x24c1c004 1 0>,
				<DCC_READ 0x24c1d004 1 0>,
				<DCC_READ 0x24c1e004 1 0>,
				<DCC_READ 0x24c1f004 1 0>,
				<DCC_READ 0x24c20004 1 0>,
				<DCC_READ 0x24c21004 1 0>,
				<DCC_READ 0x24c22004 1 0>,
				<DCC_READ 0x24c23004 1 0>,
				<DCC_READ 0x24C43350 1 0>,
				<DCC_READ 0x24C43354 1 0>,
				<DCC_READ 0x24C433F4 1 0>,
				<DCC_READ 0x24C433F8 1 0>,
				<DCC_READ 0x24C433FC 1 0>,
				<DCC_READ 0x24C43400 1 0>,
				<DCC_READ 0x24C43404 1 0>,
				<DCC_READ 0x24C43408 1 0>,
				<DCC_READ 0x24C4340C 1 0>,
				<DCC_READ 0x24C43410 1 0>,
				<DCC_READ 0x24C43414 1 0>,
				<DCC_READ 0x24C43418 1 0>,
				<DCC_READ 0x24C4341C 1 0>,
				<DCC_READ 0x24C434C0 1 0>,
				<DCC_READ 0x24C434C4 1 0>,
				<DCC_READ 0x24C434C8 1 0>,
				<DCC_READ 0x24C434CC 1 0>,
				<DCC_READ 0x24C434D0 1 0>,
				<DCC_READ 0x24C434D4 1 0>,
				<DCC_READ 0x24C43600 1 0>,
				<DCC_READ 0x24C4360C 1 0>,
				<DCC_READ 0x24C45040 1 0>,
				<DCC_READ 0x24C45048 1 0>,
				<DCC_READ 0x24C45050 1 0>,
				<DCC_READ 0x24C45058 1 0>,
				<DCC_READ 0x24C45060 1 0>,
				<DCC_READ 0x24C45068 1 0>,
				<DCC_READ 0x24C45070 1 0>,
				<DCC_READ 0x24C45074 1 0>,
				<DCC_READ 0x24C45078 1 0>,
				<DCC_READ 0x24C4507C 1 0>,
				<DCC_READ 0x24C45090 1 0>,
				<DCC_READ 0x24C45094 1 0>,
				<DCC_READ 0x24C45098 1 0>,
				<DCC_READ 0x24C4509C 1 0>,
				<DCC_READ 0x24C450A0 1 0>,
				<DCC_READ 0x24C450A4 1 0>,
				<DCC_READ 0x24C450A8 1 0>,
				<DCC_READ 0x24C450AC 1 0>,
				<DCC_READ 0x24C450B0 1 0>,
				<DCC_READ 0x24C450B4 1 0>,
				<DCC_READ 0x24C450B8 1 0>,
				<DCC_READ 0x24C450BC 1 0>,
				<DCC_READ 0x24C450C0 1 0>,
				<DCC_READ 0x24C450C4 1 0>,
				<DCC_READ 0x24C450CC 1 0>,
				<DCC_READ 0x24C450D0 1 0>,
				<DCC_READ 0x24C45240 1 0>,
				<DCC_READ 0x24C452A0 1 0>,
				<DCC_READ 0x24C45300 1 0>,
				<DCC_READ 0x24C45310 1 0>,
				<DCC_READ 0x24C45320 1 0>,
				<DCC_READ 0x24C45330 1 0>,
				<DCC_READ 0x24C45334 1 0>,
				<DCC_READ 0x24C45338 1 0>,
				<DCC_READ 0x24C47404 1 0>,
				<DCC_READ 0x24C4740C 1 0>,
				<DCC_READ 0x24C47410 1 0>,
				<DCC_READ 0x24C47414 1 0>,
				<DCC_READ 0x24C47448 1 0>,
				<DCC_READ 0x24C47450 1 0>,
				<DCC_READ 0x24C47458 1 0>,
				<DCC_READ 0x24C4745C 1 0>,
				<DCC_READ 0x24C47600 1 0>,
				<DCC_READ 0x24C49000 1 0>,
				<DCC_READ 0x24C49010 1 0>,
				<DCC_READ 0x24C7C000 1 0>,
				<DCC_READ 0x24C7C01C 1 0>,
				<DCC_READ 0x24C7C020 1 0>,
				<DCC_READ 0x24C7C024 1 0>,
				<DCC_READ 0x24C7C030 1 0>,
				<DCC_READ 0x24C7C034 1 0>,
				<DCC_READ 0x24C7C038 1 0>,
				<DCC_READ 0x24C7C03C 1 0>,
				<DCC_READ 0x24C7C040 1 0>,
				<DCC_READ 0x24C7C044 1 0>,
				<DCC_READ 0x24C7C048 1 0>,
				<DCC_READ 0x24C7C04C 1 0>,
				<DCC_READ 0x24C7C054 1 0>,
				<DCC_READ 0x24C7C058 1 0>,
				<DCC_READ 0x24C7C078 1 0>,
				<DCC_READ 0x24C7C108 1 0>,
				<DCC_READ 0x24C7C10C 1 0>,
				<DCC_READ 0x24C7C110 1 0>,
				<DCC_READ 0x24C7C114 1 0>,
				<DCC_READ 0x24C7C118 1 0>,
				<DCC_READ 0x24C7C11C 1 0>,
				<DCC_READ 0x24C7C120 1 0>,
				<DCC_READ 0x24C7C124 1 0>,
				<DCC_READ 0x24C7C128 1 0>,
				<DCC_READ 0x24C7C20C 1 0>,
				<DCC_READ 0x24C7C210 1 0>,
				<DCC_READ 0x24C7C214 1 0>,
				<DCC_READ 0x24CA600C 1 0>,
				<DCC_READ 0x24CA6010 1 0>,
				<DCC_READ 0x24CA6014 1 0>,
				<DCC_READ 0x24CA6018 1 0>,
				<DCC_READ 0x24CA6020 1 0>,
				<DCC_READ 0x24CA6024 1 0>,
				<DCC_READ 0x24CA6028 1 0>,
				<DCC_READ 0x24CA6034 1 0>,
				<DCC_READ 0x24CA6038 1 0>,
				<DCC_READ 0x24CA6040 1 0>,
				<DCC_READ 0x24CA6050 1 0>,
				<DCC_READ 0x24CA6058 1 0>,
				<DCC_READ 0x24CA6060 1 0>,
				<DCC_READ 0x24CA6064 1 0>,
				<DCC_READ 0x24CA6068 1 0>,
				<DCC_READ 0x24CA606C 1 0>,
				<DCC_READ 0x24CA7020 1 0>,
				<DCC_READ 0x24CA7030 1 0>,
				<DCC_READ 0x24CA7034 1 0>,
				<DCC_READ 0x24CA7078 1 0>,
				<DCC_READ 0x24CA707C 1 0>,
				<DCC_READ 0x24ca7080 1 0>,
				<DCC_READ 0x24CA7084 1 0>,
				<DCC_READ 0x24ca708c 1 0>,
				<DCC_READ 0x24CA7090 1 0>,
				<DCC_READ 0x24CA7094 1 0>,
				<DCC_READ 0x24CA7098 1 0>,
				<DCC_READ 0x24CA709C 1 0>,
				<DCC_READ 0x24CA70A0 1 0>,
				<DCC_READ 0x24CE002C 1 0>,
				<DCC_READ 0x24CE009C 1 0>,
				<DCC_READ 0x24CE00A0 1 0>,
				<DCC_READ 0x24CE00A8 1 0>,
				<DCC_READ 0x24CE00AC 1 0>,
				<DCC_READ 0x24CE00B0 1 0>,
				<DCC_READ 0x24CE00B8 1 0>,
				<DCC_READ 0x24CE00C0 1 0>,
				<DCC_READ 0x24CE00C4 1 0>,
				<DCC_READ 0x24CE00C8 1 0>,
				<DCC_READ 0x24CE00CC 1 0>,
				<DCC_READ 0x24CE00D0 1 0>,
				<DCC_READ 0x24CE00D4 1 0>,
				<DCC_READ 0x24CE00D8 1 0>,
				<DCC_READ 0x24CE00E0 1 0>,
				<DCC_READ 0x24CE00E8 1 0>,
				<DCC_READ 0x24CE00F0 1 0>,
				<DCC_READ 0x24CE00F8 1 0>,
				<DCC_READ 0x24CE0100 1 0>,
				<DCC_READ 0x24CE0108 1 0>,
				<DCC_READ 0x24CE0110 1 0>,
				<DCC_READ 0x24CE0118 1 0>,
				<DCC_READ 0x24CE0120 1 0>,
				<DCC_READ 0x24CE0128 1 0>,
				<DCC_READ 0x24CE0150 1 0>,
				<DCC_READ 0x24CE0154 1 0>,
				<DCC_READ 0x24CE0158 1 0>,
				<DCC_READ 0x24CE015C 1 0>,
				<DCC_READ 0x24CE0164 1 0>,
				<DCC_READ 0x24CE01E8 1 0>,
				<DCC_READ 0x24CE1010 1 0>,
				<DCC_READ 0x24CE1060 1 0>,
				<DCC_READ 0x24CE1064 1 0>,
				<DCC_READ 0x24CE1068 1 0>,
				<DCC_READ 0x24CE1070 1 0>,
				<DCC_READ 0x24CE1084 1 0>,
				<DCC_READ 0x24CE1088 1 0>,
				<DCC_READ 0x24CE108C 1 0>,
				<DCC_READ 0x24CE3004 1 0>,
				<DCC_READ 0x24CE300C 1 0>,
				<DCC_READ 0x24CE4004 1 0>,
				<DCC_READ 0x24CE4010 1 0>,
				<DCC_READ 0x24CE4014 1 0>,
				<DCC_READ 0x24CE4024 1 0>,
				<DCC_READ 0x24CE4028 1 0>,
				<DCC_READ 0x24CE4038 1 0>,
				<DCC_READ 0x24CE403C 1 0>,
				<DCC_READ 0x24CE600C 1 0>,
				<DCC_READ 0x24CE6010 1 0>,
				<DCC_READ 0x24CE6014 1 0>,
				<DCC_READ 0x24CE6018 1 0>,
				<DCC_READ 0x24CE601C 1 0>,
				<DCC_READ 0x24CE700C 1 0>,
				<DCC_READ 0x24CE7010 1 0>,
				<DCC_READ 0x24CE7014 1 0>,
				<DCC_READ 0x24CE7018 1 0>,
				<DCC_READ 0x24CE701C 1 0>,
				<DCC_READ 0x24CE9004 1 0>,
				<DCC_READ 0x24CE9010 1 0>,
				<DCC_READ 0x24CE9014 1 0>,
				<DCC_READ 0x24CE9018 1 0>,
				<DCC_READ 0x24CE9020 1 0>,
				<DCC_READ 0x24CE9024 1 0>,
				<DCC_READ 0x24CE9028 1 0>,
				<DCC_READ 0x24CE9030 1 0>,
				<DCC_READ 0x24CE9034 1 0>,
				<DCC_READ 0x24CE9038 1 0>,
				<DCC_READ 0x24CE9040 1 0>,
				<DCC_READ 0x24CE9044 1 0>,
				<DCC_READ 0x24CE9048 1 0>,
				<DCC_READ 0x24CE9050 1 0>,
				<DCC_READ 0x24CE9054 1 0>,
				<DCC_READ 0x24CE9058 1 0>,
				<DCC_READ 0x24CEA004 1 0>,
				<DCC_READ 0x24CEA010 1 0>,
				<DCC_READ 0x24CEA014 1 0>,
				<DCC_READ 0x24CEA018 1 0>,
				<DCC_READ 0x24CEA020 1 0>,
				<DCC_READ 0x24CEA024 1 0>,
				<DCC_READ 0x24CEA028 1 0>,
				<DCC_READ 0x24CEA030 1 0>,
				<DCC_READ 0x24CEA034 1 0>,
				<DCC_READ 0x24CEA038 1 0>,
				<DCC_READ 0x24CEA040 1 0>,
				<DCC_READ 0x24CEA044 1 0>,
				<DCC_READ 0x24CEA048 1 0>,
				<DCC_READ 0x24CEA050 1 0>,
				<DCC_READ 0x24CEA054 1 0>,
				<DCC_READ 0x24CEA058 1 0>,
				<DCC_READ 0x24CF001C 1 0>,
				<DCC_READ 0x24CF0050 1 0>,
				<DCC_READ 0x24CF0058 1 0>,
				<DCC_READ 0x25800004 1 0>,
				<DCC_READ 0x25801004 1 0>,
				<DCC_READ 0x25802004 1 0>,
				<DCC_READ 0x25803004 1 0>,
				<DCC_READ 0x25804004 1 0>,
				<DCC_READ 0x25805004 1 0>,
				<DCC_READ 0x25806004 1 0>,
				<DCC_READ 0x25807004 1 0>,
				<DCC_READ 0x25808004 1 0>,
				<DCC_READ 0x25809004 1 0>,
				<DCC_READ 0x2580a004 1 0>,
				<DCC_READ 0x2580b004 1 0>,
				<DCC_READ 0x2580c004 1 0>,
				<DCC_READ 0x2580d004 1 0>,
				<DCC_READ 0x2580e004 1 0>,
				<DCC_READ 0x2580f004 1 0>,
				<DCC_READ 0x25810004 1 0>,
				<DCC_READ 0x25811004 1 0>,
				<DCC_READ 0x25812004 1 0>,
				<DCC_READ 0x25813004 1 0>,
				<DCC_READ 0x25814004 1 0>,
				<DCC_READ 0x25815004 1 0>,
				<DCC_READ 0x25816004 1 0>,
				<DCC_READ 0x25817004 1 0>,
				<DCC_READ 0x25818004 1 0>,
				<DCC_READ 0x25819004 1 0>,
				<DCC_READ 0x2581a004 1 0>,
				<DCC_READ 0x2581b004 1 0>,
				<DCC_READ 0x2581c004 1 0>,
				<DCC_READ 0x2581d004 1 0>,
				<DCC_READ 0x2581e004 1 0>,
				<DCC_READ 0x2581f004 1 0>,
				<DCC_READ 0x25820004 1 0>,
				<DCC_READ 0x25821004 1 0>,
				<DCC_READ 0x25822004 1 0>,
				<DCC_READ 0x25823004 1 0>,
				<DCC_READ 0x25843350 1 0>,
				<DCC_READ 0x25843354 1 0>,
				<DCC_READ 0x258433F4 1 0>,
				<DCC_READ 0x258433F8 1 0>,
				<DCC_READ 0x258433FC 1 0>,
				<DCC_READ 0x25843400 1 0>,
				<DCC_READ 0x25843404 1 0>,
				<DCC_READ 0x25843408 1 0>,
				<DCC_READ 0x2584340C 1 0>,
				<DCC_READ 0x25843410 1 0>,
				<DCC_READ 0x25843414 1 0>,
				<DCC_READ 0x25843418 1 0>,
				<DCC_READ 0x2584341C 1 0>,
				<DCC_READ 0x258434C0 1 0>,
				<DCC_READ 0x258434C4 1 0>,
				<DCC_READ 0x258434C8 1 0>,
				<DCC_READ 0x258434CC 1 0>,
				<DCC_READ 0x258434D0 1 0>,
				<DCC_READ 0x258434D4 1 0>,
				<DCC_READ 0x25843600 1 0>,
				<DCC_READ 0x2584360C 1 0>,
				<DCC_READ 0x25845040 1 0>,
				<DCC_READ 0x25845048 1 0>,
				<DCC_READ 0x25845050 1 0>,
				<DCC_READ 0x25845058 1 0>,
				<DCC_READ 0x25845060 1 0>,
				<DCC_READ 0x25845068 1 0>,
				<DCC_READ 0x25845070 1 0>,
				<DCC_READ 0x25845074 1 0>,
				<DCC_READ 0x25845078 1 0>,
				<DCC_READ 0x2584507C 1 0>,
				<DCC_READ 0x25845090 1 0>,
				<DCC_READ 0x25845094 1 0>,
				<DCC_READ 0x25845098 1 0>,
				<DCC_READ 0x2584509C 1 0>,
				<DCC_READ 0x258450A0 1 0>,
				<DCC_READ 0x258450A4 1 0>,
				<DCC_READ 0x258450A8 1 0>,
				<DCC_READ 0x258450AC 1 0>,
				<DCC_READ 0x258450B0 1 0>,
				<DCC_READ 0x258450B4 1 0>,
				<DCC_READ 0x258450B8 1 0>,
				<DCC_READ 0x258450BC 1 0>,
				<DCC_READ 0x258450C0 1 0>,
				<DCC_READ 0x258450C4 1 0>,
				<DCC_READ 0x258450CC 1 0>,
				<DCC_READ 0x258450D0 1 0>,
				<DCC_READ 0x25845240 1 0>,
				<DCC_READ 0x258452A0 1 0>,
				<DCC_READ 0x25845300 1 0>,
				<DCC_READ 0x25845310 1 0>,
				<DCC_READ 0x25845320 1 0>,
				<DCC_READ 0x25845330 1 0>,
				<DCC_READ 0x25845334 1 0>,
				<DCC_READ 0x25845338 1 0>,
				<DCC_READ 0x25847404 1 0>,
				<DCC_READ 0x2584740C 1 0>,
				<DCC_READ 0x25847410 1 0>,
				<DCC_READ 0x25847414 1 0>,
				<DCC_READ 0x25847448 1 0>,
				<DCC_READ 0x25847450 1 0>,
				<DCC_READ 0x25847458 1 0>,
				<DCC_READ 0x2584745C 1 0>,
				<DCC_READ 0x25847600 1 0>,
				<DCC_READ 0x25849000 1 0>,
				<DCC_READ 0x25849010 1 0>,
				<DCC_READ 0x2587C000 1 0>,
				<DCC_READ 0x2587C01C 1 0>,
				<DCC_READ 0x2587C020 1 0>,
				<DCC_READ 0x2587C024 1 0>,
				<DCC_READ 0x2587C030 1 0>,
				<DCC_READ 0x2587C034 1 0>,
				<DCC_READ 0x2587C038 1 0>,
				<DCC_READ 0x2587C03C 1 0>,
				<DCC_READ 0x2587C040 1 0>,
				<DCC_READ 0x2587C044 1 0>,
				<DCC_READ 0x2587C048 1 0>,
				<DCC_READ 0x2587C04C 1 0>,
				<DCC_READ 0x2587C054 1 0>,
				<DCC_READ 0x2587C058 1 0>,
				<DCC_READ 0x2587C078 1 0>,
				<DCC_READ 0x2587C108 1 0>,
				<DCC_READ 0x2587C10C 1 0>,
				<DCC_READ 0x2587C110 1 0>,
				<DCC_READ 0x2587C114 1 0>,
				<DCC_READ 0x2587C118 1 0>,
				<DCC_READ 0x2587C11C 1 0>,
				<DCC_READ 0x2587C120 1 0>,
				<DCC_READ 0x2587C124 1 0>,
				<DCC_READ 0x2587C128 1 0>,
				<DCC_READ 0x2587C20C 1 0>,
				<DCC_READ 0x2587C210 1 0>,
				<DCC_READ 0x2587C214 1 0>,
				<DCC_READ 0x258A600C 1 0>,
				<DCC_READ 0x258A6010 1 0>,
				<DCC_READ 0x258A6014 1 0>,
				<DCC_READ 0x258A6018 1 0>,
				<DCC_READ 0x258A6020 1 0>,
				<DCC_READ 0x258A6024 1 0>,
				<DCC_READ 0x258A6028 1 0>,
				<DCC_READ 0x258A6034 1 0>,
				<DCC_READ 0x258A6038 1 0>,
				<DCC_READ 0x258A6040 1 0>,
				<DCC_READ 0x258A6050 1 0>,
				<DCC_READ 0x258A6058 1 0>,
				<DCC_READ 0x258A6060 1 0>,
				<DCC_READ 0x258A6064 1 0>,
				<DCC_READ 0x258A6068 1 0>,
				<DCC_READ 0x258A606C 1 0>,
				<DCC_READ 0x258A7020 1 0>,
				<DCC_READ 0x258A7030 1 0>,
				<DCC_READ 0x258A7034 1 0>,
				<DCC_READ 0x258A7078 1 0>,
				<DCC_READ 0x258A707C 1 0>,
				<DCC_READ 0x258a7080 1 0>,
				<DCC_READ 0x258A7084 1 0>,
				<DCC_READ 0x258a708c 1 0>,
				<DCC_READ 0x258A7090 1 0>,
				<DCC_READ 0x258A7094 1 0>,
				<DCC_READ 0x258A7098 1 0>,
				<DCC_READ 0x258A709C 1 0>,
				<DCC_READ 0x258A70A0 1 0>,
				<DCC_READ 0x258E002C 1 0>,
				<DCC_READ 0x258E009C 1 0>,
				<DCC_READ 0x258E00A0 1 0>,
				<DCC_READ 0x258E00A8 1 0>,
				<DCC_READ 0x258E00AC 1 0>,
				<DCC_READ 0x258E00B0 1 0>,
				<DCC_READ 0x258E00B8 1 0>,
				<DCC_READ 0x258E00C0 1 0>,
				<DCC_READ 0x258E00C4 1 0>,
				<DCC_READ 0x258E00C8 1 0>,
				<DCC_READ 0x258E00CC 1 0>,
				<DCC_READ 0x258E00D0 1 0>,
				<DCC_READ 0x258E00D4 1 0>,
				<DCC_READ 0x258E00D8 1 0>,
				<DCC_READ 0x258E00E0 1 0>,
				<DCC_READ 0x258E00E8 1 0>,
				<DCC_READ 0x258E00F0 1 0>,
				<DCC_READ 0x258E00F8 1 0>,
				<DCC_READ 0x258E0100 1 0>,
				<DCC_READ 0x258E0108 1 0>,
				<DCC_READ 0x258E0110 1 0>,
				<DCC_READ 0x258E0118 1 0>,
				<DCC_READ 0x258E0120 1 0>,
				<DCC_READ 0x258E0128 1 0>,
				<DCC_READ 0x258E0150 1 0>,
				<DCC_READ 0x258E0154 1 0>,
				<DCC_READ 0x258E0158 1 0>,
				<DCC_READ 0x258E015C 1 0>,
				<DCC_READ 0x258E0164 1 0>,
				<DCC_READ 0x258E01E8 1 0>,
				<DCC_READ 0x258E1010 1 0>,
				<DCC_READ 0x258E1060 1 0>,
				<DCC_READ 0x258E1064 1 0>,
				<DCC_READ 0x258E1068 1 0>,
				<DCC_READ 0x258E1070 1 0>,
				<DCC_READ 0x258E1084 1 0>,
				<DCC_READ 0x258E1088 1 0>,
				<DCC_READ 0x258E108C 1 0>,
				<DCC_READ 0x258E3004 1 0>,
				<DCC_READ 0x258E300C 1 0>,
				<DCC_READ 0x258E4004 1 0>,
				<DCC_READ 0x258E4010 1 0>,
				<DCC_READ 0x258E4014 1 0>,
				<DCC_READ 0x258E4024 1 0>,
				<DCC_READ 0x258E4028 1 0>,
				<DCC_READ 0x258E4038 1 0>,
				<DCC_READ 0x258E403C 1 0>,
				<DCC_READ 0x258E600C 1 0>,
				<DCC_READ 0x258E6010 1 0>,
				<DCC_READ 0x258E6014 1 0>,
				<DCC_READ 0x258E6018 1 0>,
				<DCC_READ 0x258E601C 1 0>,
				<DCC_READ 0x258E700C 1 0>,
				<DCC_READ 0x258E7010 1 0>,
				<DCC_READ 0x258E7014 1 0>,
				<DCC_READ 0x258E7018 1 0>,
				<DCC_READ 0x258E701C 1 0>,
				<DCC_READ 0x258E9004 1 0>,
				<DCC_READ 0x258E9010 1 0>,
				<DCC_READ 0x258E9014 1 0>,
				<DCC_READ 0x258E9018 1 0>,
				<DCC_READ 0x258E9020 1 0>,
				<DCC_READ 0x258E9024 1 0>,
				<DCC_READ 0x258E9028 1 0>,
				<DCC_READ 0x258E9030 1 0>,
				<DCC_READ 0x258E9034 1 0>,
				<DCC_READ 0x258E9038 1 0>,
				<DCC_READ 0x258E9040 1 0>,
				<DCC_READ 0x258E9044 1 0>,
				<DCC_READ 0x258E9048 1 0>,
				<DCC_READ 0x258E9050 1 0>,
				<DCC_READ 0x258E9054 1 0>,
				<DCC_READ 0x258E9058 1 0>,
				<DCC_READ 0x258EA004 1 0>,
				<DCC_READ 0x258EA010 1 0>,
				<DCC_READ 0x258EA014 1 0>,
				<DCC_READ 0x258EA018 1 0>,
				<DCC_READ 0x258EA020 1 0>,
				<DCC_READ 0x258EA024 1 0>,
				<DCC_READ 0x258EA028 1 0>,
				<DCC_READ 0x258EA030 1 0>,
				<DCC_READ 0x258EA034 1 0>,
				<DCC_READ 0x258EA038 1 0>,
				<DCC_READ 0x258EA040 1 0>,
				<DCC_READ 0x258EA044 1 0>,
				<DCC_READ 0x258EA048 1 0>,
				<DCC_READ 0x258EA050 1 0>,
				<DCC_READ 0x258EA054 1 0>,
				<DCC_READ 0x258EA058 1 0>,
				<DCC_READ 0x258F001C 1 0>,
				<DCC_READ 0x258F0050 1 0>,
				<DCC_READ 0x258F0058 1 0>,
				<DCC_READ 0x25c00004 1 0>,
				<DCC_READ 0x25c01004 1 0>,
				<DCC_READ 0x25c02004 1 0>,
				<DCC_READ 0x25c03004 1 0>,
				<DCC_READ 0x25c04004 1 0>,
				<DCC_READ 0x25c05004 1 0>,
				<DCC_READ 0x25c06004 1 0>,
				<DCC_READ 0x25c07004 1 0>,
				<DCC_READ 0x25c08004 1 0>,
				<DCC_READ 0x25c09004 1 0>,
				<DCC_READ 0x25c0a004 1 0>,
				<DCC_READ 0x25c0b004 1 0>,
				<DCC_READ 0x25c0c004 1 0>,
				<DCC_READ 0x25c0d004 1 0>,
				<DCC_READ 0x25c0e004 1 0>,
				<DCC_READ 0x25c0f004 1 0>,
				<DCC_READ 0x25c10004 1 0>,
				<DCC_READ 0x25c11004 1 0>,
				<DCC_READ 0x25c12004 1 0>,
				<DCC_READ 0x25c13004 1 0>,
				<DCC_READ 0x25c14004 1 0>,
				<DCC_READ 0x25c15004 1 0>,
				<DCC_READ 0x25c16004 1 0>,
				<DCC_READ 0x25c17004 1 0>,
				<DCC_READ 0x25c18004 1 0>,
				<DCC_READ 0x25c19004 1 0>,
				<DCC_READ 0x25c1a004 1 0>,
				<DCC_READ 0x25c1b004 1 0>,
				<DCC_READ 0x25c1c004 1 0>,
				<DCC_READ 0x25c1d004 1 0>,
				<DCC_READ 0x25c1e004 1 0>,
				<DCC_READ 0x25c1f004 1 0>,
				<DCC_READ 0x25c20004 1 0>,
				<DCC_READ 0x25c21004 1 0>,
				<DCC_READ 0x25c22004 1 0>,
				<DCC_READ 0x25c23004 1 0>,
				<DCC_READ 0x25C43350 1 0>,
				<DCC_READ 0x25C43354 1 0>,
				<DCC_READ 0x25C433F4 1 0>,
				<DCC_READ 0x25C433F8 1 0>,
				<DCC_READ 0x25C433FC 1 0>,
				<DCC_READ 0x25C43400 1 0>,
				<DCC_READ 0x25C43404 1 0>,
				<DCC_READ 0x25C43408 1 0>,
				<DCC_READ 0x25C4340C 1 0>,
				<DCC_READ 0x25C43410 1 0>,
				<DCC_READ 0x25C43414 1 0>,
				<DCC_READ 0x25C43418 1 0>,
				<DCC_READ 0x25C4341C 1 0>,
				<DCC_READ 0x25C434C0 1 0>,
				<DCC_READ 0x25C434C4 1 0>,
				<DCC_READ 0x25C434C8 1 0>,
				<DCC_READ 0x25C434CC 1 0>,
				<DCC_READ 0x25C434D0 1 0>,
				<DCC_READ 0x25C434D4 1 0>,
				<DCC_READ 0x25C43600 1 0>,
				<DCC_READ 0x25C4360C 1 0>,
				<DCC_READ 0x25C45040 1 0>,
				<DCC_READ 0x25C45048 1 0>,
				<DCC_READ 0x25C45050 1 0>,
				<DCC_READ 0x25C45058 1 0>,
				<DCC_READ 0x25C45060 1 0>,
				<DCC_READ 0x25C45068 1 0>,
				<DCC_READ 0x25C45070 1 0>,
				<DCC_READ 0x25C45074 1 0>,
				<DCC_READ 0x25C45078 1 0>,
				<DCC_READ 0x25C4507C 1 0>,
				<DCC_READ 0x25C45090 1 0>,
				<DCC_READ 0x25C45094 1 0>,
				<DCC_READ 0x25C45098 1 0>,
				<DCC_READ 0x25C4509C 1 0>,
				<DCC_READ 0x25C450A0 1 0>,
				<DCC_READ 0x25C450A4 1 0>,
				<DCC_READ 0x25C450A8 1 0>,
				<DCC_READ 0x25C450AC 1 0>,
				<DCC_READ 0x25C450B0 1 0>,
				<DCC_READ 0x25C450B4 1 0>,
				<DCC_READ 0x25C450B8 1 0>,
				<DCC_READ 0x25C450BC 1 0>,
				<DCC_READ 0x25C450C0 1 0>,
				<DCC_READ 0x25C450C4 1 0>,
				<DCC_READ 0x25C450CC 1 0>,
				<DCC_READ 0x25C450D0 1 0>,
				<DCC_READ 0x25C45240 1 0>,
				<DCC_READ 0x25C452A0 1 0>,
				<DCC_READ 0x25C45300 1 0>,
				<DCC_READ 0x25C45310 1 0>,
				<DCC_READ 0x25C45320 1 0>,
				<DCC_READ 0x25C45330 1 0>,
				<DCC_READ 0x25C45334 1 0>,
				<DCC_READ 0x25C45338 1 0>,
				<DCC_READ 0x25C47404 1 0>,
				<DCC_READ 0x25C4740C 1 0>,
				<DCC_READ 0x25C47410 1 0>,
				<DCC_READ 0x25C47414 1 0>,
				<DCC_READ 0x25C47448 1 0>,
				<DCC_READ 0x25C47450 1 0>,
				<DCC_READ 0x25C47458 1 0>,
				<DCC_READ 0x25C4745C 1 0>,
				<DCC_READ 0x25C47600 1 0>,
				<DCC_READ 0x25C49000 1 0>,
				<DCC_READ 0x25C49010 1 0>,
				<DCC_READ 0x25C7C000 1 0>,
				<DCC_READ 0x25C7C01C 1 0>,
				<DCC_READ 0x25C7C020 1 0>,
				<DCC_READ 0x25C7C024 1 0>,
				<DCC_READ 0x25C7C030 1 0>,
				<DCC_READ 0x25C7C034 1 0>,
				<DCC_READ 0x25C7C038 1 0>,
				<DCC_READ 0x25C7C03C 1 0>,
				<DCC_READ 0x25C7C040 1 0>,
				<DCC_READ 0x25C7C044 1 0>,
				<DCC_READ 0x25C7C048 1 0>,
				<DCC_READ 0x25C7C04C 1 0>,
				<DCC_READ 0x25C7C054 1 0>,
				<DCC_READ 0x25C7C058 1 0>,
				<DCC_READ 0x25C7C078 1 0>,
				<DCC_READ 0x25C7C108 1 0>,
				<DCC_READ 0x25C7C10C 1 0>,
				<DCC_READ 0x25C7C110 1 0>,
				<DCC_READ 0x25C7C114 1 0>,
				<DCC_READ 0x25C7C118 1 0>,
				<DCC_READ 0x25C7C11C 1 0>,
				<DCC_READ 0x25C7C120 1 0>,
				<DCC_READ 0x25C7C124 1 0>,
				<DCC_READ 0x25C7C128 1 0>,
				<DCC_READ 0x25C7C20C 1 0>,
				<DCC_READ 0x25C7C210 1 0>,
				<DCC_READ 0x25C7C214 1 0>,
				<DCC_READ 0x25CA600C 1 0>,
				<DCC_READ 0x25CA6010 1 0>,
				<DCC_READ 0x25CA6014 1 0>,
				<DCC_READ 0x25CA6018 1 0>,
				<DCC_READ 0x25CA6020 1 0>,
				<DCC_READ 0x25CA6024 1 0>,
				<DCC_READ 0x25CA6028 1 0>,
				<DCC_READ 0x25CA6034 1 0>,
				<DCC_READ 0x25CA6038 1 0>,
				<DCC_READ 0x25CA6040 1 0>,
				<DCC_READ 0x25CA6050 1 0>,
				<DCC_READ 0x25CA6058 1 0>,
				<DCC_READ 0x25CA6060 1 0>,
				<DCC_READ 0x25CA6064 1 0>,
				<DCC_READ 0x25CA6068 1 0>,
				<DCC_READ 0x25CA606C 1 0>,
				<DCC_READ 0x25CA7020 1 0>,
				<DCC_READ 0x25CA7030 1 0>,
				<DCC_READ 0x25CA7034 1 0>,
				<DCC_READ 0x25CA7078 1 0>,
				<DCC_READ 0x25CA707C 1 0>,
				<DCC_READ 0x25ca7080 1 0>,
				<DCC_READ 0x25CA7084 1 0>,
				<DCC_READ 0x25ca708c 1 0>,
				<DCC_READ 0x25CA7090 1 0>,
				<DCC_READ 0x25CA7094 1 0>,
				<DCC_READ 0x25CA7098 1 0>,
				<DCC_READ 0x25CA709C 1 0>,
				<DCC_READ 0x25CA70A0 1 0>,
				<DCC_READ 0x25CE002C 1 0>,
				<DCC_READ 0x25CE009C 1 0>,
				<DCC_READ 0x25CE00A0 1 0>,
				<DCC_READ 0x25CE00A8 1 0>,
				<DCC_READ 0x25CE00AC 1 0>,
				<DCC_READ 0x25CE00B0 1 0>,
				<DCC_READ 0x25CE00B8 1 0>,
				<DCC_READ 0x25CE00C0 1 0>,
				<DCC_READ 0x25CE00C4 1 0>,
				<DCC_READ 0x25CE00C8 1 0>,
				<DCC_READ 0x25CE00CC 1 0>,
				<DCC_READ 0x25CE00D0 1 0>,
				<DCC_READ 0x25CE00D4 1 0>,
				<DCC_READ 0x25CE00D8 1 0>,
				<DCC_READ 0x25CE00E0 1 0>,
				<DCC_READ 0x25CE00E8 1 0>,
				<DCC_READ 0x25CE00F0 1 0>,
				<DCC_READ 0x25CE00F8 1 0>,
				<DCC_READ 0x25CE0100 1 0>,
				<DCC_READ 0x25CE0108 1 0>,
				<DCC_READ 0x25CE0110 1 0>,
				<DCC_READ 0x25CE0118 1 0>,
				<DCC_READ 0x25CE0120 1 0>,
				<DCC_READ 0x25CE0128 1 0>,
				<DCC_READ 0x25CE0150 1 0>,
				<DCC_READ 0x25CE0154 1 0>,
				<DCC_READ 0x25CE0158 1 0>,
				<DCC_READ 0x25CE015C 1 0>,
				<DCC_READ 0x25CE0164 1 0>,
				<DCC_READ 0x25CE01E8 1 0>,
				<DCC_READ 0x25CE1010 1 0>,
				<DCC_READ 0x25CE1060 1 0>,
				<DCC_READ 0x25CE1064 1 0>,
				<DCC_READ 0x25CE1068 1 0>,
				<DCC_READ 0x25CE1070 1 0>,
				<DCC_READ 0x25CE1084 1 0>,
				<DCC_READ 0x25CE1088 1 0>,
				<DCC_READ 0x25CE108C 1 0>,
				<DCC_READ 0x25CE3004 1 0>,
				<DCC_READ 0x25CE300C 1 0>,
				<DCC_READ 0x25CE4004 1 0>,
				<DCC_READ 0x25CE4010 1 0>,
				<DCC_READ 0x25CE4014 1 0>,
				<DCC_READ 0x25CE4024 1 0>,
				<DCC_READ 0x25CE4028 1 0>,
				<DCC_READ 0x25CE4038 1 0>,
				<DCC_READ 0x25CE403C 1 0>,
				<DCC_READ 0x25CE600C 1 0>,
				<DCC_READ 0x25CE6010 1 0>,
				<DCC_READ 0x25CE6014 1 0>,
				<DCC_READ 0x25CE6018 1 0>,
				<DCC_READ 0x25CE601C 1 0>,
				<DCC_READ 0x25CE700C 1 0>,
				<DCC_READ 0x25CE7010 1 0>,
				<DCC_READ 0x25CE7014 1 0>,
				<DCC_READ 0x25CE7018 1 0>,
				<DCC_READ 0x25CE701C 1 0>,
				<DCC_READ 0x25CE9004 1 0>,
				<DCC_READ 0x25CE9010 1 0>,
				<DCC_READ 0x25CE9014 1 0>,
				<DCC_READ 0x25CE9018 1 0>,
				<DCC_READ 0x25CE9020 1 0>,
				<DCC_READ 0x25CE9024 1 0>,
				<DCC_READ 0x25CE9028 1 0>,
				<DCC_READ 0x25CE9030 1 0>,
				<DCC_READ 0x25CE9034 1 0>,
				<DCC_READ 0x25CE9038 1 0>,
				<DCC_READ 0x25CE9040 1 0>,
				<DCC_READ 0x25CE9044 1 0>,
				<DCC_READ 0x25CE9048 1 0>,
				<DCC_READ 0x25CE9050 1 0>,
				<DCC_READ 0x25CE9054 1 0>,
				<DCC_READ 0x25CE9058 1 0>,
				<DCC_READ 0x25CEA004 1 0>,
				<DCC_READ 0x25CEA010 1 0>,
				<DCC_READ 0x25CEA014 1 0>,
				<DCC_READ 0x25CEA018 1 0>,
				<DCC_READ 0x25CEA020 1 0>,
				<DCC_READ 0x25CEA024 1 0>,
				<DCC_READ 0x25CEA028 1 0>,
				<DCC_READ 0x25CEA030 1 0>,
				<DCC_READ 0x25CEA034 1 0>,
				<DCC_READ 0x25CEA038 1 0>,
				<DCC_READ 0x25CEA040 1 0>,
				<DCC_READ 0x25CEA044 1 0>,
				<DCC_READ 0x25CEA048 1 0>,
				<DCC_READ 0x25CEA050 1 0>,
				<DCC_READ 0x25CEA054 1 0>,
				<DCC_READ 0x25CEA058 1 0>,
				<DCC_READ 0x25CF001C 1 0>,
				<DCC_READ 0x25CF0050 1 0>,
				<DCC_READ 0x25CF0058 1 0>,
				<DCC_READ 0x240A0008 1 0>,
				<DCC_READ 0x240A000C 1 0>,
				<DCC_READ 0x240A1008 1 0>,
				<DCC_READ 0x240A100C 1 0>,
				<DCC_READ 0x248e0070 1 0>,
				<DCC_READ 0x248e0074 1 0>,
				<DCC_READ 0x248e0078 1 0>,
				<DCC_READ 0x248e007c 1 0>,
				<DCC_READ 0x248e0080 1 0>,
				<DCC_READ 0x248e0084 1 0>,
				<DCC_READ 0x248e0088 1 0>,
				<DCC_READ 0x248e0094 1 0>,
				<DCC_READ 0x248e0098 1 0>,
				<DCC_READ 0x248e012c 1 0>,
				<DCC_READ 0x248e0130 1 0>,
				<DCC_READ 0x248e0134 1 0>,
				<DCC_READ 0x248e0138 1 0>,
				<DCC_READ 0x248e013c 1 0>,
				<DCC_READ 0x248e0140 1 0>,
				<DCC_READ 0x248e0144 1 0>,
				<DCC_READ 0x248e0148 1 0>,
				<DCC_READ 0x248e014c 1 0>,
				<DCC_READ 0x248e0160 1 0>,
				<DCC_READ 0x248e0364 1 0>,
				<DCC_READ 0x248e0368 1 0>,
				<DCC_READ 0x24ce0070 1 0>,
				<DCC_READ 0x24ce0074 1 0>,
				<DCC_READ 0x24ce0078 1 0>,
				<DCC_READ 0x24ce007c 1 0>,
				<DCC_READ 0x24ce0080 1 0>,
				<DCC_READ 0x24ce0084 1 0>,
				<DCC_READ 0x24ce0088 1 0>,
				<DCC_READ 0x24ce0094 1 0>,
				<DCC_READ 0x24ce0098 1 0>,
				<DCC_READ 0x24ce012c 1 0>,
				<DCC_READ 0x24ce0130 1 0>,
				<DCC_READ 0x24ce0134 1 0>,
				<DCC_READ 0x24ce0138 1 0>,
				<DCC_READ 0x24ce013c 1 0>,
				<DCC_READ 0x24ce0140 1 0>,
				<DCC_READ 0x24ce0144 1 0>,
				<DCC_READ 0x24ce0148 1 0>,
				<DCC_READ 0x24ce014c 1 0>,
				<DCC_READ 0x24ce0160 1 0>,
				<DCC_READ 0x24ce0364 1 0>,
				<DCC_READ 0x24ce0368 1 0>,
				<DCC_READ 0x258e0070 1 0>,
				<DCC_READ 0x258e0074 1 0>,
				<DCC_READ 0x258e0078 1 0>,
				<DCC_READ 0x258e007c 1 0>,
				<DCC_READ 0x258e0080 1 0>,
				<DCC_READ 0x258e0084 1 0>,
				<DCC_READ 0x258e0088 1 0>,
				<DCC_READ 0x258e0094 1 0>,
				<DCC_READ 0x258e0098 1 0>,
				<DCC_READ 0x258e012c 1 0>,
				<DCC_READ 0x258e0130 1 0>,
				<DCC_READ 0x258e0134 1 0>,
				<DCC_READ 0x258e0138 1 0>,
				<DCC_READ 0x258e013c 1 0>,
				<DCC_READ 0x258e0140 1 0>,
				<DCC_READ 0x258e0144 1 0>,
				<DCC_READ 0x258e0148 1 0>,
				<DCC_READ 0x258e014c 1 0>,
				<DCC_READ 0x258e0160 1 0>,
				<DCC_READ 0x258e0364 1 0>,
				<DCC_READ 0x258e0368 1 0>,
				<DCC_READ 0x25ce0070 1 0>,
				<DCC_READ 0x25ce0074 1 0>,
				<DCC_READ 0x25ce0078 1 0>,
				<DCC_READ 0x25ce007c 1 0>,
				<DCC_READ 0x25ce0080 1 0>,
				<DCC_READ 0x25ce0084 1 0>,
				<DCC_READ 0x25ce0088 1 0>,
				<DCC_READ 0x25ce0094 1 0>,
				<DCC_READ 0x25ce0098 1 0>,
				<DCC_READ 0x25ce012c 1 0>,
				<DCC_READ 0x25ce0130 1 0>,
				<DCC_READ 0x25ce0134 1 0>,
				<DCC_READ 0x25ce0138 1 0>,
				<DCC_READ 0x25ce013c 1 0>,
				<DCC_READ 0x25ce0140 1 0>,
				<DCC_READ 0x25ce0144 1 0>,
				<DCC_READ 0x25ce0148 1 0>,
				<DCC_READ 0x25ce014c 1 0>,
				<DCC_READ 0x25ce0160 1 0>,
				<DCC_READ 0x25ce0364 1 0>,
				<DCC_READ 0x25ce0368 1 0>,
				<DCC_READ 0x248e0358 1 0>,
				<DCC_READ 0x24ce0358 1 0>,
				<DCC_READ 0x258e0358 1 0>,
				<DCC_READ 0x25ce0358 1 0>,
				<DCC_READ 0x248e0008 1 0>,
				<DCC_READ 0x24ce0008 1 0>,
				<DCC_READ 0x258e0008 1 0>,
				<DCC_READ 0x25ce0008 1 0>,
				<DCC_READ 0x24076B00 2 0>,
				<DCC_READ 0x24076B0C 2 0>,
				<DCC_READ 0x24076B18 2 0>,
				<DCC_READ 0x24076B24 2 0>,
				<DCC_READ 0x24076B30 2 0>,
				<DCC_READ 0x24076B3C 2 0>,
				<DCC_READ 0x24076B48 2 0>,
				<DCC_READ 0x24076B54 2 0>,
				<DCC_READ 0x24076B60 2 0>,
				<DCC_READ 0x24076B6C 2 0>,
				<DCC_READ 0x24076B78 2 0>,
				<DCC_READ 0x24076B84 2 0>,
				<DCC_READ 0x24076B90 2 0>,
				<DCC_READ 0x24076B9C 2 0>,
				<DCC_READ 0x24076BA8 2 0>,
				<DCC_READ 0x24076BB4 2 0>,
				<DCC_READ 0x24076BC0 2 0>,
				<DCC_READ 0x24076BCC 2 0>,
				<DCC_READ 0x24076BD8 2 0>,
				<DCC_READ 0x24076BE4 2 0>,
				<DCC_READ 0x24076BF0 2 0>,
				<DCC_READ 0x24076BFC 2 0>,
				<DCC_READ 0x24076C08 2 0>,
				<DCC_READ 0x24076C14 2 0>,
				<DCC_READ 0x24076C20 2 0>,
				<DCC_READ 0x24076C2C 2 0>,
				<DCC_READ 0x24076C38 2 0>,
				<DCC_READ 0x24076C44 2 0>,
				<DCC_READ 0x24076C50 2 0>,
				<DCC_READ 0x24076C5C 2 0>,
				<DCC_READ 0x24076C68 2 0>,
				<DCC_READ 0x24076C74 2 0>,
				<DCC_READ 0x24076950 1 0>,
				<DCC_READ 0x240760A4 1 0>,
				<DCC_READ 0x248720B0 1 0>,
				<DCC_READ 0x258720B0 1 0>,
				<DCC_READ 0x24C720B0 1 0>,
				<DCC_READ 0x25C720B0 1 0>;
		};

		link_list_1 {
			qcom,curr-link-list = <4>;
			qcom,data-sink = "sram";
			qcom,ap-qad-override;
			qcom,link-list = <DCC_READ 0x16801000 2 0>,
				<DCC_READ 0x240e0010 1 0>,
				<DCC_READ 0x240e0020 8 0>,
				<DCC_READ 0x240e0248 1 0>,
				<DCC_READ 0x24330010 1 0>,
				<DCC_READ 0x24330020 8 0>,
				<DCC_READ 0x24330248 1 0>,
				<DCC_READ 0x240e1018 1 0>,
				<DCC_READ 0x240e1008 1 0>,
				<DCC_LOOP 0x9 0 0>,
				<DCC_READ 0x240e1010 2 0>,
				<DCC_LOOP 0x1 0 0>,
				<DCC_READ 0x24331018 1 0>,
				<DCC_READ 0x24331008 1 0>,
				<DCC_LOOP 0x8 0 0>,
				<DCC_READ 0x24331010 2 0>,
				<DCC_LOOP 0x1 0 0>,
				<DCC_READ 0x01780010 1 0>,
				<DCC_READ 0x01780020 8 0>,
				<DCC_READ 0x01780248 1 0>,
				<DCC_READ 0x01782018 1 0>,
				<DCC_READ 0x01782008 1 0>,
				<DCC_LOOP 0xc 0 0>,
				<DCC_READ 0x01782010 2 0>,
				<DCC_LOOP 0x1 0 0>,
				<DCC_READ 0x01783018 1 0>,
				<DCC_READ 0x01783008 1 0>,
				<DCC_LOOP 0x11 0 0>,
				<DCC_READ 0x01783010 2 0>,
				<DCC_LOOP 0x1 0 0>,
				<DCC_READ 0x01680010 1 0>,
				<DCC_READ 0x01680020 8 0>,
				<DCC_READ 0x01681048 1 0>,
				<DCC_READ 0x01682018 1 0>,
				<DCC_READ 0x01682008 1 0>,
				<DCC_LOOP 0x6 0 0>,
				<DCC_READ 0x01682010 2 0>,
				<DCC_LOOP 0x1 0 0>,
				<DCC_READ 0x016e0010 1 0>,
				<DCC_READ 0x016e0020 8 0>,
				<DCC_READ 0x016e0248 1 0>,
				<DCC_READ 0x016e1018 1 0>,
				<DCC_READ 0x016e1008 1 0>,
				<DCC_LOOP 0x4 0 0>,
				<DCC_READ 0x016e1010 2 0>,
				<DCC_LOOP 0x1 0 0>,
				<DCC_READ 0x016e1098 1 0>,
				<DCC_READ 0x016e1088 1 0>,
				<DCC_LOOP 0x3 0 0>,
				<DCC_READ 0x016e1090 2 0>,
				<DCC_LOOP 0x1 0 0>,
				<DCC_READ 0x016e1118 1 0>,
				<DCC_READ 0x016e1108 1 0>,
				<DCC_LOOP 0x7 0 0>,
				<DCC_READ 0x016e1110 2 0>,
				<DCC_LOOP 0x1 0 0>,
				<DCC_READ 0x01700010 1 0>,
				<DCC_READ 0x01700020 8 0>,
				<DCC_READ 0x01700248 1 0>,
				<DCC_READ 0x1702018 1 0>,
				<DCC_READ 0x1702008 1 0>,
				<DCC_LOOP 0x4 0 0>,
				<DCC_READ 0x1702010 2 0>,
				<DCC_LOOP 0x1 0 0>,
				<DCC_READ 0x1702218 1 0>,
				<DCC_READ 0x1702208 1 0>,
				<DCC_LOOP 0x2 0 0>,
				<DCC_READ 0x1702210 2 0>,
				<DCC_LOOP 0x1 0 0>,
				<DCC_READ 0x1702118 1 0>,
				<DCC_READ 0x1702108 1 0>,
				<DCC_LOOP 0x3 0 0>,
				<DCC_READ 0x1702110 2 0>,
				<DCC_LOOP 0x1 0 0>,
				<DCC_READ 0x01600010 1 0>,
				<DCC_READ 0x01600020 8 0>,
				<DCC_READ 0x01600248 2 0>,
				<DCC_READ 0x01600258 1 0>,
				<DCC_READ 0x01602018 1 0>,
				<DCC_READ 0x01602008 1 0>,
				<DCC_LOOP 0x7 0 0>,
				<DCC_READ 0x01602010 2 0>,
				<DCC_LOOP 0x1 0 0>,
				<DCC_READ 0x01602098 1 0>,
				<DCC_READ 0x01602088 1 0>,
				<DCC_LOOP 0x2 0 0>,
				<DCC_READ 0x01602090 2 0>,
				<DCC_LOOP 0x1 0 0>,
				<DCC_READ 0x01602118 1 0>,
				<DCC_READ 0x01602108 1 0>,
				<DCC_LOOP 0x3 0 0>,
				<DCC_READ 0x01602110 2 0>,
				<DCC_LOOP 0x1 0 0>,
				<DCC_READ 0x01602198 1 0>,
				<DCC_READ 0x01602188 1 0>,
				<DCC_LOOP 0x3 0 0>,
				<DCC_READ 0x01602190 2 0>,
				<DCC_LOOP 0x1 0 0>,
				<DCC_READ 0x01602218 1 0>,
				<DCC_READ 0x01602208 1 0>,
				<DCC_LOOP 0x2 0 0>,
				<DCC_READ 0x01602210 2 0>,
				<DCC_LOOP 0x1 0 0>,
				<DCC_READ 0x1602098 1 0>,
				<DCC_READ 0x1602088 1 0>,
				<DCC_LOOP 0x2 0 0>,
				<DCC_READ 0x1602090 2 0>,
				<DCC_LOOP 0x1 0 0>,
				<DCC_READ 0x01500010 1 0>,
				<DCC_READ 0x01500020 8 0>,
				<DCC_READ 0x01500248 1 0>,
				<DCC_READ 0x01500448 1 0>,
				<DCC_READ 0x01502018 1 0>,
				<DCC_READ 0x01502008 1 0>,
				<DCC_LOOP 0x7 0 0>,
				<DCC_READ 0x01502010 2 0>,
				<DCC_LOOP 0x1 0 0>,
				<DCC_READ 0x01502098 1 0>,
				<DCC_READ 0x01502088 1 0>,
				<DCC_LOOP 0x7 0 0>,
				<DCC_READ 0x01502090 2 0>,
				<DCC_LOOP 0x1 0 0>,
				<DCC_READ 0x16E00010 1 0>,
				<DCC_READ 0x16E00020 8 0>,
				<DCC_READ 0x16E00248 1 0>,
				<DCC_READ 0x16E01018 1 0>,
				<DCC_READ 0x16E01008 1 0>,
				<DCC_LOOP 0x6 0 0>,
				<DCC_READ 0x16E01010 2 0>,
				<DCC_LOOP 0x1 0 0>,
				<DCC_READ 0x1B600010 1 0>,
				<DCC_READ 0x1B600020 8 0>,
				<DCC_READ 0x1B600248 1 0>,
				<DCC_READ 0x1B601018 1 0>,
				<DCC_READ 0x1B601008 1 0>,
				<DCC_LOOP 0x6 0 0>,
				<DCC_READ 0x1B601010 2 0>,
				<DCC_LOOP 0x1 0 0>,
				<DCC_READ 0x16000104 30 0>,
				<DCC_READ 0x16000204 29 0>,
				<DCC_READ 0x16000384 30 0>,
				<DCC_READ 0xB291024 1 0>,
				<DCC_READ 0xC201244 1 0>,
				<DCC_READ 0xC202244 1 0>,
				<DCC_READ 0xBDE1034 1 0>,
				<DCC_READ 0xBDE1038 1 0>,
				<DCC_READ 0xB201020 2 0>,
				<DCC_READ 0xB211020 2 0>,
				<DCC_READ 0xB221020 2 0>,
				<DCC_READ 0xB231020 2 0>,
				<DCC_READ 0xB204520 1 0>,
				<DCC_READ 0xB200000 1 0>,
				<DCC_READ 0xB210000 1 0>,
				<DCC_READ 0xB220000 1 0>,
				<DCC_READ 0xB230000 1 0>,
				<DCC_READ 0x16500010 1 0>,
				<DCC_READ 0x16510010 1 0>,
				<DCC_READ 0x16520010 1 0>,
				<DCC_READ 0x16530010 1 0>,
				<DCC_READ 0x16500030 1 0>,
				<DCC_READ 0x16510030 1 0>,
				<DCC_READ 0x16520030 1 0>,
				<DCC_READ 0x16530030 1 0>,
				<DCC_READ 0x16500038 1 0>,
				<DCC_READ 0x16510038 1 0>,
				<DCC_READ 0x16520038 1 0>,
				<DCC_READ 0x16530038 1 0>,
				<DCC_READ 0x16500040 1 0>,
				<DCC_READ 0x16510040 1 0>,
				<DCC_READ 0x16520040 1 0>,
				<DCC_READ 0x16530040 1 0>,
				<DCC_READ 0x16500048 1 0>,
				<DCC_READ 0x16500400 3 0>,
				<DCC_READ 0x16510400 3 0>,
				<DCC_READ 0x16520400 3 0>,
				<DCC_READ 0x16530400 3 0>,
				<DCC_READ 0x16510d3c 1 0>,
				<DCC_READ 0x16510d54 1 0>,
				<DCC_READ 0x16510d6c 1 0>,
				<DCC_READ 0x16510d84 1 0>,
				<DCC_READ 0x16510d9c 1 0>,
				<DCC_READ 0x16510db4 1 0>,
				<DCC_READ 0x16510dcc 1 0>,
				<DCC_READ 0x16510de4 1 0>,
				<DCC_READ 0x16510dfc 1 0>,
				<DCC_READ 0x16510e14 1 0>,
				<DCC_READ 0x16510e2c 1 0>,
				<DCC_READ 0x16510e44 1 0>,
				<DCC_READ 0x16510e5c 1 0>,
				<DCC_READ 0x16510e74 1 0>,
				<DCC_READ 0x16510e8c 1 0>,
				<DCC_READ 0x16510ea4 1 0>,
				<DCC_READ 0x16510fdc 1 0>,
				<DCC_READ 0x16510ff4 1 0>,
				<DCC_READ 0x1651100c 1 0>,
				<DCC_READ 0x16511024 1 0>,
				<DCC_READ 0x1651103c 1 0>,
				<DCC_READ 0x16511054 1 0>,
				<DCC_READ 0x1651106c 1 0>,
				<DCC_READ 0x16511084 1 0>,
				<DCC_READ 0x1651109c 1 0>,
				<DCC_READ 0x165110b4 1 0>,
				<DCC_READ 0x165110cc 1 0>,
				<DCC_READ 0x165110e4 1 0>,
				<DCC_READ 0x165110fc 1 0>,
				<DCC_READ 0x16511114 1 0>,
				<DCC_READ 0x1651112c 1 0>,
				<DCC_READ 0x16511144 1 0>,
				<DCC_READ 0x1651127c 1 0>,
				<DCC_READ 0x16511294 1 0>,
				<DCC_READ 0x165112ac 1 0>,
				<DCC_READ 0x165112c4 1 0>,
				<DCC_READ 0x165112dc 1 0>,
				<DCC_READ 0x165112f4 1 0>,
				<DCC_READ 0x1651130c 1 0>,
				<DCC_READ 0x16511324 1 0>,
				<DCC_READ 0x1651133c 1 0>,
				<DCC_READ 0x16511354 1 0>,
				<DCC_READ 0x1651136c 1 0>,
				<DCC_READ 0x16511384 1 0>,
				<DCC_READ 0x1651139c 1 0>,
				<DCC_READ 0x165113b4 1 0>,
				<DCC_READ 0x165113cc 1 0>,
				<DCC_READ 0x165113e4 1 0>,
				<DCC_READ 0x1651151c 1 0>,
				<DCC_READ 0x16511534 1 0>,
				<DCC_READ 0x1651154c 1 0>,
				<DCC_READ 0x16511564 1 0>,
				<DCC_READ 0x1651157c 1 0>,
				<DCC_READ 0x16511594 1 0>,
				<DCC_READ 0x165115ac 1 0>,
				<DCC_READ 0x165115c4 1 0>,
				<DCC_READ 0x165115dc 1 0>,
				<DCC_READ 0x165115f4 1 0>,
				<DCC_READ 0x1651160c 1 0>,
				<DCC_READ 0x16511624 1 0>,
				<DCC_READ 0x1651163c 1 0>,
				<DCC_READ 0x16511654 1 0>,
				<DCC_READ 0x1651166c 1 0>,
				<DCC_READ 0x16511684 1 0>,
				<DCC_READ 0x110004 2 0>,
				<DCC_READ 0x11003C 3 0>,
				<DCC_READ 0x176040 1 0>,
				<DCC_READ 0x10C0000 4 0>,
				<DCC_READ 0x10C1000 2 0>,
				<DCC_READ 0x10C1010 7 0>,
				<DCC_READ 0x10C1100 3 0>,
				<DCC_READ 0x10C1110 5 0>,
				<DCC_READ 0x10C1130 2 0>,
				<DCC_READ 0x10C113C 2 0>,
				<DCC_READ 0x10C1148 3 0>,
				<DCC_READ 0x10C1800 11 0>,
				<DCC_READ 0x10C2000 1 0>,
				<DCC_READ 0x10CF004 1 0>,
				<DCC_READ 0x16801000 2 0>;
		};
	};

	mem_dump {
		compatible = "qcom,mem-dump";
		memory-region = <&dump_mem>;

		static_dump {
			qcom,static-mem-dump;

			c0_context {
				qcom,dump-size = <0x800>;
				qcom,dump-id = <0x0>;
			};

			c100_context {
				qcom,dump-size = <0x800>;
				qcom,dump-id = <0x1>;
			};

			c200_context {
				qcom,dump-size = <0x800>;
				qcom,dump-id = <0x2>;
			};

			c300_context {
				qcom,dump-size = <0x800>;
				qcom,dump-id = <0x3>;
			};

			c400_context {
				qcom,dump-size = <0x800>;
				qcom,dump-id = <0x4>;
			};

			c500_context {
				qcom,dump-size = <0x800>;
				qcom,dump-id = <0x5>;
			};

			c600_context {
				qcom,dump-size = <0x800>;
				qcom,dump-id = <0x6>;
			};

			c700_context {
				qcom,dump-size = <0x800>;
				qcom,dump-id = <0x7>;
			};

			rpmh {
				qcom,dump-size = <0x400000>;
				qcom,dump-id = <0xec>;
			};

			rpm_sw {
				qcom,dump-size = <0x28000>;
				qcom,dump-id = <0xea>;
			};

			pmic {
				qcom,dump-size = <0x200000>;
				qcom,dump-id = <0xe4>;
			};

			fcm {
				qcom,dump-size = <0x8400>;
				qcom,dump-id = <0xee>;
			};

			misc_data {
				qcom,dump-size = <0x1000>;
				qcom,dump-id = <0xe8>;
			};

			etf_swao {
				qcom,dump-size = <0x10000>;
				qcom,dump-id = <0xf1>;
			};

			etr_reg {
				qcom,dump-size = <0x1000>;
				qcom,dump-id = <0x100>;
			};

			etfswao_reg {
				qcom,dump-size = <0x1000>;
				qcom,dump-id = <0x102>;
			};

			etr1_reg {
				qcom,dump-size = <0x1000>;
				qcom,dump-id = <0x105>;
			};

			etf_slpi {
				qcom,dump-size = <0x4000>;
				qcom,dump-id = <0xf3>;
			};

			etfslpi_reg {
				qcom,dump-size = <0x1000>;
				qcom,dump-id = <0x103>;
			};

			etf_lpass {
				qcom,dump-size = <0x4000>;
				qcom,dump-id = <0xf4>;
			};

			etflpass_reg {
				qcom,dump-size = <0x1000>;
				qcom,dump-id = <0x104>;
			};

			osm_reg {
				qcom,dump-size = <0x400>;
				qcom,dump-id = <0x163>;
			};

			pcu_reg {
				qcom,dump-size = <0x400>;
				qcom,dump-id = <0x164>;
			};

			fsm_data {
				qcom,dump-size = <0x400>;
				qcom,dump-id = <0x165>;
			};

			scandump_smmu {
				qcom,dump-size = <0x40000>;
				qcom,dump-id = <0x220>;
			};

			apps_scandump {
				qcom,dump-size = <0x380000>;
				qcom,dump-id = <0x130>;
			};
		};

		dynamic_mem_dump {
			qcom,dynamic-mem-dump;

			scandump_gpu {
				scandump_gpu {
					qcom,dump-size = <0x300000>;
					qcom,dump-id = <0x221>;
				};
			};

			cpuss_reg {
				cpuss_reg {
					qcom,dump-size = <0xa00000>;
					qcom,dump-id = <0xef>;
				};
			};

			spr {
				spr_cpu0 {
					qcom,dump-size = <0x2000>;
					qcom,dump-id = <0x1f0>;
				};

				spr_cpu1 {
					qcom,dump-size = <0x2000>;
					qcom,dump-id = <0x1f1>;
				};

				spr_cpu2 {
					qcom,dump-size = <0x2000>;
					qcom,dump-id = <0x1f2>;
				};

				spr_cpu3 {
					qcom,dump-size = <0x2000>;
					qcom,dump-id = <0x1f3>;
				};

				spr_cpu4 {
					qcom,dump-size = <0x2000>;
					qcom,dump-id = <0x1f4>;
				};

				spr_cpu5 {
					qcom,dump-size = <0x2000>;
					qcom,dump-id = <0x1f5>;
				};

				spr_cpu6 {
					qcom,dump-size = <0x2000>;
					qcom,dump-id = <0x1f6>;
				};

				spr_cpu7 {
					qcom,dump-size = <0x2000>;
					qcom,dump-id = <0x1f7>;
				};
			};

			cpuss_cpu {
				cpuss_cpu0 {
					qcom,dump-size = <0x40000>;
					qcom,dump-id = <0x280>;
				};

				cpuss_cpu1 {
					qcom,dump-size = <0x40000>;
					qcom,dump-id = <0x281>;
				};

				cpuss_cpu2 {
					qcom,dump-size = <0x40000>;
					qcom,dump-id = <0x282>;
				};

				cpuss_cpu3 {
					qcom,dump-size = <0x40000>;
					qcom,dump-id = <0x283>;
				};

				cpuss_cpu4 {
					qcom,dump-size = <0x40000>;
					qcom,dump-id = <0x284>;
				};

				cpuss_cpu5 {
					qcom,dump-size = <0x40000>;
					qcom,dump-id = <0x285>;
				};

				cpuss_cpu6 {
					qcom,dump-size = <0x40000>;
					qcom,dump-id = <0x286>;
				};

				cpuss_cpu7 {
					qcom,dump-size = <0x40000>;
					qcom,dump-id = <0x287>;
				};
			};

			cpuss_cluster {
				cpuss_cluster0 {
					qcom,dump-size = <0x40000>;
					qcom,dump-id = <0x270>;
				};

				cpuss_cluster1 {
					qcom,dump-size = <0x40000>;
					qcom,dump-id = <0x271>;
				};
			};

			cpucp {
				cpucp {
					qcom,dump-size = <0x80000>;
					qcom,dump-id = <0xf5>;
				};
			};

			cpu_cache {
				cache_cpu0 {
					qcom,dump-size = <0x2aa000>;
					qcom,dump-id = <0x230>;
				};

				cache_cpu1 {
					qcom,dump-size = <0x2aa000>;
					qcom,dump-id = <0x231>;
				};

				cache_cpu2 {
					qcom,dump-size = <0x2aa000>;
					qcom,dump-id = <0x232>;
				};

				cache_cpu3 {
					qcom,dump-size = <0x2aa000>;
					qcom,dump-id = <0x233>;
				};

				cache_cpu4 {
					qcom,dump-size = <0x2aa000>;
					qcom,dump-id = <0x234>;
				};

				cache_cpu5 {
					qcom,dump-size = <0x2aa000>;
					qcom,dump-id = <0x235>;
				};

				cache_cpu6 {
					qcom,dump-size = <0x2aa000>;
					qcom,dump-id = <0x236>;
				};

				cache_cpu7 {
					qcom,dump-size = <0x2aa000>;
					qcom,dump-id = <0x237>;
				};
			};

			cluster_cache {
				cl_cache0 {
					qcom,dump-size = <0x1400000>;
					qcom,dump-id = <0x240>;
				};

				cl_cache1 {
					qcom,dump-size = <0x1400000>;
					qcom,dump-id = <0x241>;
				};

			};
		};
	};
};
